AUTOSAR XML (schema 00048)
standard types defined: boolean, sint16, uint16, uint8
package /VehicleProject
  system System
package /NM
  nm config NmConfig: can-nm-cluster-coupling=coupled-cluster=[TC37X_VCU_CAN00_CAN, TC37X_VCU_CAN01_CAN, TC37X_VCU_CAN03_CAN, TC37X_VCU_CAN12_CAN]
    4 x can nm cluster, all with nm-msg-cycle-time=0.5, nm-network-timeout=2, nm-repeat-message-time=1.5, nm-user-data-length=6, nm-wait-bus-sleep-time=2:
      TC37X_VCU_CAN00_CAN: communication-cluster=TC37X_VCU_CAN00, nm-channel-id=0
        can nm node GWM: nm-if-ecu=GWM_CAN, nm-node-id=28, rx-nm-pdu=VCU_Tx_51Ch_NM_oTC37X_VCU_CAN00, tx-nm-pdu=VCU_Rx_500h_NM_oTC37X_VCU_CAN00, nm-msg-cycle-offset=0, nm-msg-reduced-time=0.32, nm-range-config={lower-can-id=1024, upper-can-id=1151}
        can nm node Tester: nm-if-ecu=Tester_CAN, nm-node-id=28, nm-passive-mode-enabled=true, nm-msg-cycle-offset=0, nm-msg-reduced-time=0.32, nm-range-config={lower-can-id=1024, upper-can-id=1151}
        can nm node VCU: controller=CT_TC37X_VCU_CAN00, nm-if-ecu=VCU_CAN, nm-node-id=28, rx-nm-pdu=VCU_Rx_500h_NM_oTC37X_VCU_CAN00, tx-nm-pdu=VCU_Tx_51Ch_NM_oTC37X_VCU_CAN00, nm-msg-cycle-offset=0, nm-msg-reduced-time=0.32, nm-range-config={lower-can-id=1024, upper-can-id=1151}
      TC37X_VCU_CAN01_CAN: communication-cluster=TC37X_VCU_CAN01, nm-channel-id=1
        can nm node GWM: nm-if-ecu=GWM_CAN, nm-node-id=28, rx-nm-pdu=VCU_Tx_51Ch_NM_oTC37X_VCU_CAN01, tx-nm-pdu=VCU_Rx_500h_NM_oTC37X_VCU_CAN01, nm-msg-cycle-offset=0, nm-msg-reduced-time=0.32, nm-range-config={lower-can-id=1024, upper-can-id=1151}
        can nm node Tester: nm-if-ecu=Tester_CAN, nm-node-id=28, nm-passive-mode-enabled=true, nm-msg-cycle-offset=0, nm-msg-reduced-time=0.32, nm-range-config={lower-can-id=1024, upper-can-id=1151}
        can nm node VCU: controller=CT_TC37X_VCU_CAN01, nm-if-ecu=VCU_CAN, nm-node-id=28, rx-nm-pdu=VCU_Rx_500h_NM_oTC37X_VCU_CAN01, tx-nm-pdu=VCU_Tx_51Ch_NM_oTC37X_VCU_CAN01, nm-msg-cycle-offset=0, nm-msg-reduced-time=0.32, nm-range-config={lower-can-id=1024, upper-can-id=1151}
      TC37X_VCU_CAN03_CAN: communication-cluster=TC37X_VCU_CAN03, nm-channel-id=3
        can nm node GWM: nm-if-ecu=GWM_CAN, nm-node-id=28, rx-nm-pdu=VCU_Tx_51Ch_NM_oTC37X_VCU_CAN03, tx-nm-pdu=VCU_Rx_500h_NM_oTC37X_VCU_CAN03, nm-msg-cycle-offset=0, nm-msg-reduced-time=0.32, nm-range-config={lower-can-id=1024, upper-can-id=1151}
        can nm node Tester: nm-if-ecu=Tester_CAN, nm-node-id=28, nm-passive-mode-enabled=true, nm-msg-cycle-offset=0, nm-msg-reduced-time=0.32, nm-range-config={lower-can-id=1024, upper-can-id=1151}
        can nm node VCU: controller=CT_TC37X_VCU_CAN03, nm-if-ecu=VCU_CAN, nm-node-id=28, rx-nm-pdu=VCU_Rx_500h_NM_oTC37X_VCU_CAN03, tx-nm-pdu=VCU_Tx_51Ch_NM_oTC37X_VCU_CAN03, nm-msg-cycle-offset=0, nm-msg-reduced-time=0.32, nm-range-config={lower-can-id=1024, upper-can-id=1151}
      TC37X_VCU_CAN12_CAN: communication-cluster=TC37X_VCU_CAN12, nm-channel-id=2
        can nm node GWM: nm-if-ecu=GWM_CAN, nm-node-id=28, rx-nm-pdu=VCU_Tx_51Ch_NM_oTC37X_VCU_CAN12, tx-nm-pdu=VCU_Rx_500h_NM_oTC37X_VCU_CAN12, nm-msg-cycle-offset=0, nm-msg-reduced-time=0.32, nm-range-config={lower-can-id=1024, upper-can-id=1151}
        can nm node Tester: nm-if-ecu=Tester_CAN, nm-node-id=28, nm-passive-mode-enabled=true, nm-msg-cycle-offset=0, nm-msg-reduced-time=0.32, nm-range-config={lower-can-id=1024, upper-can-id=1151}
        can nm node VCU: controller=CT_TC37X_VCU_CAN12, nm-if-ecu=VCU_CAN, nm-node-id=28, rx-nm-pdu=VCU_Rx_500h_NM_oTC37X_VCU_CAN12, tx-nm-pdu=VCU_Tx_51Ch_NM_oTC37X_VCU_CAN12, nm-msg-cycle-offset=0, nm-msg-reduced-time=0.32, nm-range-config={lower-can-id=1024, upper-can-id=1151}
    nm-if-ecus:
      nm ecu GWM_CAN: nm-node-id-enabled=true, nm-user-data-enabled=true
      nm ecu Tester_CAN: nm-node-id-enabled=true, nm-passive-mode-enabled=true, nm-user-data-enabled=true
      nm ecu VCU_CAN: ecu-instance=VCU, nm-node-id-enabled=true, nm-user-data-enabled=true
package /TP
  can tp config TC37X_VCU_CAN00_CAN: communication-cluster=TC37X_VCU_CAN00, can-tp-ecu{cycle-time-main-function=0.005, ecu-instance=VCU}
    can tp channel TPCH: channel-id=0, channel-mode=FULL-DUPLEX-MODE
    can-tp-connection addressing-format=STANDARD, can-tp-channel=TPCH, data-pdu=Vcu_Uds_Func_Request_Tp_oTC37X_VCU_CAN00, receiver=TN_VCU, ta-type=FUNCTIONAL, tp-sdu=Vcu_Uds_Func_Request_oTC37X_VCU_CAN00, transmitter=TN_Tester:
      ident Vcu_Uds_Func_Request_oTN_Tester
    can-tp-connection addressing-format=STANDARD, can-tp-channel=TPCH, data-pdu=Vcu_Uds_Phy_Request_Tp_oTC37X_VCU_CAN00, flow-control-pdu=Vcu_Uds_Response_Tp_oTC37X_VCU_CAN00, receiver=TN_VCU, ta-type=PHYSICAL, tp-sdu=Vcu_Uds_Phy_Request_oTC37X_VCU_CAN00, transmitter=TN_Tester:
      ident Vcu_Uds_Phy_Request_oTN_VCU
    can-tp-connection addressing-format=STANDARD, can-tp-channel=TPCH, data-pdu=Vcu_Uds_Response_Tp_oTC37X_VCU_CAN00, flow-control-pdu=Vcu_Uds_Phy_Request_Tp_oTC37X_VCU_CAN00, receiver=TN_Tester, ta-type=PHYSICAL, tp-sdu=Vcu_Uds_Response_oTC37X_VCU_CAN00, transmitter=TN_VCU:
      ident Vcu_Uds_Response_oTN_VCU
    can tp node TN_Tester
    can tp node TN_VCU: connector=CN_TC37X_VCU_CAN00
  lin tp config LIN00: communication-cluster=LIN00
    8 x tp address:
      TA_0x005B: tp-address=91
      TA_0x0062: tp-address=98
      TA_0x0063: tp-address=99
      TA_0x0064: tp-address=100
      TA_0x0065: tp-address=101
      TA_0x0074: tp-address=116
      TA_0x0075: tp-address=117
      TA_0x007E: tp-address=126
    tp-connections:
      data-pdu=MasterReq_Tp_oLIN00, lin-tp-n-sdu=MasterReq_oLIN00, multicast=LIN00/TA_0x007E, receiver=[TN_0x005B_HVCH, TN_0x0062_ERV, TN_0x0063_EXV_1, TN_0x0064_EXV_2, TN_0x0065_SVA, TN_0x0074_PMP_1, TN_0x0075_PMP_2], transmitter=LIN00/TN_Master
      data-pdu=SlaveResp_Tp_oLIN00, flow-control=MasterReq_Tp_oLIN00, lin-tp-n-sdu=SlaveResp_HVCH_oLIN00, receiver=LIN00/TN_Master, transmitter=TN_0x005B_HVCH
      data-pdu=SlaveResp_Tp_oLIN00, flow-control=MasterReq_Tp_oLIN00, lin-tp-n-sdu=SlaveResp_ERV_oLIN00, receiver=LIN00/TN_Master, transmitter=TN_0x0062_ERV
      data-pdu=SlaveResp_Tp_oLIN00, flow-control=MasterReq_Tp_oLIN00, lin-tp-n-sdu=SlaveResp_EXV_1_oLIN00, receiver=LIN00/TN_Master, transmitter=TN_0x0063_EXV_1
      data-pdu=SlaveResp_Tp_oLIN00, flow-control=MasterReq_Tp_oLIN00, lin-tp-n-sdu=SlaveResp_EXV_2_oLIN00, receiver=LIN00/TN_Master, transmitter=TN_0x0064_EXV_2
      data-pdu=SlaveResp_Tp_oLIN00, flow-control=MasterReq_Tp_oLIN00, lin-tp-n-sdu=SlaveResp_SVA_oLIN00, receiver=LIN00/TN_Master, transmitter=TN_0x0065_SVA
      data-pdu=SlaveResp_Tp_oLIN00, flow-control=MasterReq_Tp_oLIN00, lin-tp-n-sdu=SlaveResp_PMP_1_oLIN00, receiver=LIN00/TN_Master, transmitter=TN_0x0074_PMP_1
      data-pdu=SlaveResp_Tp_oLIN00, flow-control=MasterReq_Tp_oLIN00, lin-tp-n-sdu=SlaveResp_PMP_2_oLIN00, receiver=LIN00/TN_Master, transmitter=TN_0x0075_PMP_2
      data-pdu=MasterReq_Tp_oLIN00, flow-control=SlaveResp_Tp_oLIN00, lin-tp-n-sdu=MasterReq_HVCH_oLIN00, receiver=TN_0x005B_HVCH, transmitter=LIN00/TN_Master
      data-pdu=MasterReq_Tp_oLIN00, flow-control=SlaveResp_Tp_oLIN00, lin-tp-n-sdu=MasterReq_ERV_oLIN00, receiver=TN_0x0062_ERV, transmitter=LIN00/TN_Master
      data-pdu=MasterReq_Tp_oLIN00, flow-control=SlaveResp_Tp_oLIN00, lin-tp-n-sdu=MasterReq_EXV_1_oLIN00, receiver=TN_0x0063_EXV_1, transmitter=LIN00/TN_Master
      data-pdu=MasterReq_Tp_oLIN00, flow-control=SlaveResp_Tp_oLIN00, lin-tp-n-sdu=MasterReq_EXV_2_oLIN00, receiver=TN_0x0064_EXV_2, transmitter=LIN00/TN_Master
      data-pdu=MasterReq_Tp_oLIN00, flow-control=SlaveResp_Tp_oLIN00, lin-tp-n-sdu=MasterReq_SVA_oLIN00, receiver=TN_0x0065_SVA, transmitter=LIN00/TN_Master
      data-pdu=MasterReq_Tp_oLIN00, flow-control=SlaveResp_Tp_oLIN00, lin-tp-n-sdu=MasterReq_PMP_1_oLIN00, receiver=TN_0x0074_PMP_1, transmitter=LIN00/TN_Master
      data-pdu=MasterReq_Tp_oLIN00, flow-control=SlaveResp_Tp_oLIN00, lin-tp-n-sdu=MasterReq_PMP_2_oLIN00, receiver=TN_0x0075_PMP_2, transmitter=LIN00/TN_Master
    8 x lin tp node:
      TN_0x005B_HVCH: tp-address=TA_0x005B
      TN_0x0062_ERV: tp-address=TA_0x0062
      TN_0x0063_EXV_1: tp-address=TA_0x0063
      TN_0x0064_EXV_2: tp-address=TA_0x0064
      TN_0x0065_SVA: tp-address=TA_0x0065
      TN_0x0074_PMP_1: tp-address=TA_0x0074
      TN_0x0075_PMP_2: tp-address=TA_0x0075
      TN_Master: connector=CN_LIN00
  lin tp config LIN01: communication-cluster=LIN01
    tp address TA_0x0052: tp-address=82
    tp address TA_0x007E: tp-address=126
    tp-connections:
      data-pdu=MasterReq_Tp_oLIN01, lin-tp-n-sdu=MasterReq_oLIN01, multicast=LIN01/TA_0x007E, receiver=TN_0x0052_GWM, transmitter=LIN01/TN_Master
      data-pdu=SlaveResp_Tp_oLIN01, flow-control=MasterReq_Tp_oLIN01, lin-tp-n-sdu=SlaveResp_GWM_oLIN01, receiver=LIN01/TN_Master, transmitter=TN_0x0052_GWM
      data-pdu=MasterReq_Tp_oLIN01, flow-control=SlaveResp_Tp_oLIN01, lin-tp-n-sdu=MasterReq_GWM_oLIN01, receiver=TN_0x0052_GWM, transmitter=LIN01/TN_Master
    lin tp node TN_0x0052_GWM: tp-address=TA_0x0052
    lin tp node TN_Master: connector=CN_LIN01
package /Cluster
  5 x can cluster, all with baudrate=500000, protocol-name=CAN:
    KAMA_FP_EPT_0303
      can physical channel CHNL: comm-connectors=CN_KAMA_FP_EPT_0303
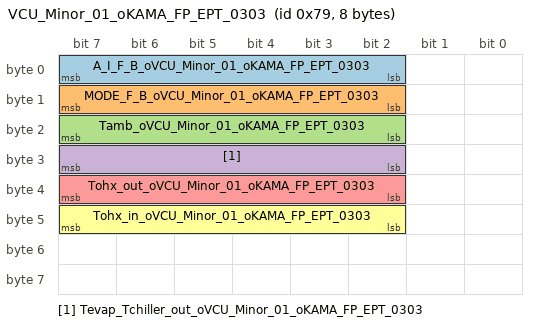
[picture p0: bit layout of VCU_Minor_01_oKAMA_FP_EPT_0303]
        frame VCU_Minor_01_oKAMA_FP_EPT_0303: id 0x79, from VCU, frame-length=8, can-addressing-mode=STANDARD
          pdu VCU_Minor_01_oKAMA_FP_EPT_0303: length=8, minimum-delay=0, transmission-mode-false-timing=cyclic-timing={time-offset=0, time-period=0.02}, transmission-mode-true-timing=cyclic-timing={time-offset=0, time-period=0.02}, unused-bit-pattern=0
            signal A_I_F_B_oVCU_Minor_01_oKAMA_FP_EPT_0303: start 7, 6 bit, big-endian, i-signal-type=PRIMITIVE, init-value=0, base-type=uint8, compu {phys=raw*0.1 for raw 0..50; unit V}, range raw 0..50, unit=V, transfer-property=PENDING
            signal MODE_F_B_oVCU_Minor_01_oKAMA_FP_EPT_0303: start 15, 6 bit, big-endian, i-signal-type=PRIMITIVE, init-value=0, base-type=uint8, compu {phys=raw*0.1 for raw 0..50; unit V}, range raw 0..50, unit=V, transfer-property=PENDING
            signal Tamb_oVCU_Minor_01_oKAMA_FP_EPT_0303: start 23, 6 bit, big-endian, i-signal-type=PRIMITIVE, init-value=0, base-type=uint8, compu {phys=raw*0.1 for raw 0..50; unit V}, range raw 0..50, unit=V, transfer-property=PENDING
            signal Tevap_Tchiller_out_oVCU_Minor_01_oKAMA_FP_EPT_0303: start 31, 6 bit, big-endian, i-signal-type=PRIMITIVE, init-value=0, base-type=uint8, compu {phys=raw*0.1 for raw 0..50; unit V}, range raw 0..50, unit=V, transfer-property=PENDING
            signal Tohx_out_oVCU_Minor_01_oKAMA_FP_EPT_0303: start 39, 6 bit, big-endian, i-signal-type=PRIMITIVE, init-value=0, base-type=uint8, compu {phys=raw*0.1 for raw 0..50; unit V}, range raw 0..50, unit=V, transfer-property=PENDING
            signal Tohx_in_oVCU_Minor_01_oKAMA_FP_EPT_0303: start 47, 6 bit, big-endian, i-signal-type=PRIMITIVE, init-value=0, base-type=uint8, compu {phys=raw*0.1 for raw 0..50; unit V}, range raw 0..50, unit=V, transfer-property=PENDING
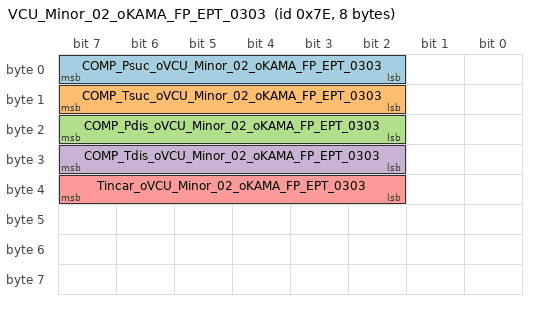
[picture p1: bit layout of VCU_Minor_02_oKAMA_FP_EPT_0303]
        frame VCU_Minor_02_oKAMA_FP_EPT_0303: id 0x7E, from VCU, frame-length=8, can-addressing-mode=STANDARD
          pdu VCU_Minor_02_oKAMA_FP_EPT_0303: length=8, minimum-delay=0, transmission-mode-false-timing=cyclic-timing={time-offset=0, time-period=0.02}, transmission-mode-true-timing=cyclic-timing={time-offset=0, time-period=0.02}, unused-bit-pattern=0
            signal COMP_Psuc_oVCU_Minor_02_oKAMA_FP_EPT_0303: start 7, 6 bit, big-endian, i-signal-type=PRIMITIVE, init-value=0, base-type=uint8, compu {phys=raw*0.1 for raw 0..50; unit V}, range raw 0..50, unit=V, transfer-property=PENDING
            signal COMP_Tsuc_oVCU_Minor_02_oKAMA_FP_EPT_0303: start 15, 6 bit, big-endian, i-signal-type=PRIMITIVE, init-value=0, base-type=uint8, compu {phys=raw*0.1 for raw 0..50; unit V}, range raw 0..50, unit=V, transfer-property=PENDING
            signal COMP_Pdis_oVCU_Minor_02_oKAMA_FP_EPT_0303: start 23, 6 bit, big-endian, i-signal-type=PRIMITIVE, init-value=0, base-type=uint8, compu {phys=raw*0.1 for raw 0..50; unit V}, range raw 0..50, unit=V, transfer-property=PENDING
            signal COMP_Tdis_oVCU_Minor_02_oKAMA_FP_EPT_0303: start 31, 6 bit, big-endian, i-signal-type=PRIMITIVE, init-value=0, base-type=uint8, compu {phys=raw*0.1 for raw 0..50; unit V}, range raw 0..50, unit=V, transfer-property=PENDING
            signal Tincar_oVCU_Minor_02_oKAMA_FP_EPT_0303: start 39, 6 bit, big-endian, i-signal-type=PRIMITIVE, init-value=0, base-type=uint8, compu {phys=raw*0.1 for raw 0..50; unit V}, range raw 0..50, unit=V, transfer-property=PENDING
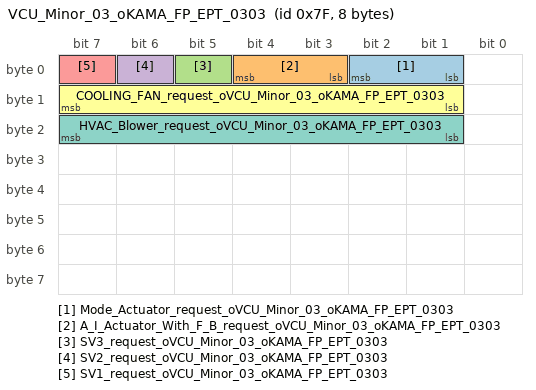
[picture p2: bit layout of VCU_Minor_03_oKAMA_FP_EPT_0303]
        frame VCU_Minor_03_oKAMA_FP_EPT_0303: id 0x7F, to VCU, frame-length=8, can-addressing-mode=STANDARD
          pdu VCU_Minor_03_oKAMA_FP_EPT_0303: length=8, minimum-delay=0, transmission-mode-false-timing=cyclic-timing={time-offset=0, time-period=0.02}, transmission-mode-true-timing=cyclic-timing={time-offset=0, time-period=0.02}, unused-bit-pattern=0
            signal Mode_Actuator_request_oVCU_Minor_03_oKAMA_FP_EPT_0303: start 2, 2 bit, big-endian, i-signal-type=PRIMITIVE, init-value=0, base-type=uint8, compu {0=Cx0_Stop, 1=Cx1_Request_corotation, 2=Cx2_Request_revrsal}, range raw 0..2, transfer-property=PENDING, to VCU
            signal A_I_Actuator_With_F_B_request_oVCU_Minor_03_oKAMA_FP_EPT_0303: start 4, 2 bit, big-endian, i-signal-type=PRIMITIVE, init-value=0, base-type=uint8, compu {0=Cx0_Stop, 1=Cx1_Request_corotation, 2=Cx2_Request_revrsal}, range raw 0..2, transfer-property=PENDING, to VCU
            signal SV3_request_oVCU_Minor_03_oKAMA_FP_EPT_0303: start 5, 1 bit, big-endian, i-signal-type=PRIMITIVE, init-value=0, base-type=boolean, compu {0=Cx0_OFF, 1=Cx1_ON}, range raw 0..1, transfer-property=PENDING, to VCU
            signal SV2_request_oVCU_Minor_03_oKAMA_FP_EPT_0303: start 6, 1 bit, big-endian, i-signal-type=PRIMITIVE, init-value=0, base-type=boolean, compu {0=Cx0_OFF, 1=Cx1_ON}, range raw 0..1, transfer-property=PENDING, to VCU
            signal SV1_request_oVCU_Minor_03_oKAMA_FP_EPT_0303: start 7, 1 bit, big-endian, i-signal-type=PRIMITIVE, init-value=0, base-type=boolean, compu {0=Cx0_OFF, 1=Cx1_ON}, range raw 0..1, transfer-property=PENDING, to VCU
            signal COOLING_FAN_request_oVCU_Minor_03_oKAMA_FP_EPT_0303: start 15, 7 bit, big-endian, i-signal-type=PRIMITIVE, init-value=0, base-type=uint8, compu {identical}, range raw 0..100, unit=%, transfer-property=PENDING, to VCU
            signal HVAC_Blower_request_oVCU_Minor_03_oKAMA_FP_EPT_0303: start 23, 7 bit, big-endian, i-signal-type=PRIMITIVE, init-value=0, base-type=uint8, compu {identical}, range raw 0..100, unit=%, transfer-property=PENDING, to VCU
    TC37X_VCU_CAN00  # VCU_CAN00
      can physical channel CHNL: comm-connectors=CN_TC37X_VCU_CAN00
        frame VCU_Rx_500h_NM_oTC37X_VCU_CAN00: id 0x500, to VCU, frame-length=8, can-addressing-mode=STANDARD
          nm pdu VCU_Rx_500h_NM_oTC37X_VCU_CAN00: length=8, unused-bit-pattern=0
        frame VCU_Tx_51Ch_NM_oTC37X_VCU_CAN00: id 0x51C, from VCU, frame-length=8, can-addressing-mode=STANDARD
          nm pdu VCU_Tx_51Ch_NM_oTC37X_VCU_CAN00: length=8, unused-bit-pattern=0
        frame Vcu_Uds_Func_Request_oTC37X_VCU_CAN00: id 0x700, to VCU, frame-length=8, can-addressing-mode=STANDARD
          n pdu Vcu_Uds_Func_Request_Tp_oTC37X_VCU_CAN00: length=8
        frame Vcu_Uds_Phy_Request_oTC37X_VCU_CAN00: id 0x701, to VCU, frame-length=8, can-addressing-mode=STANDARD
          n pdu Vcu_Uds_Phy_Request_Tp_oTC37X_VCU_CAN00: length=8
        frame Vcu_Uds_Response_oTC37X_VCU_CAN00: id 0x781, from VCU, frame-length=8, can-addressing-mode=STANDARD
          n pdu Vcu_Uds_Response_Tp_oTC37X_VCU_CAN00: length=8
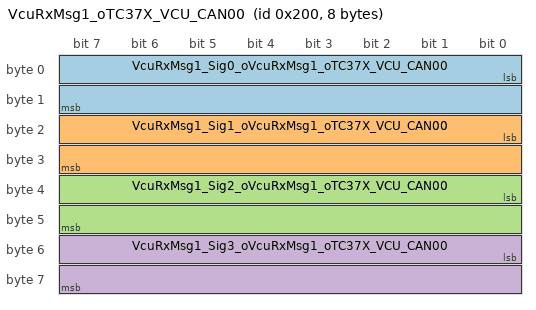
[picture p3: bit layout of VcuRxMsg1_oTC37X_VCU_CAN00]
        frame VcuRxMsg1_oTC37X_VCU_CAN00: id 0x200, to VCU, frame-length=8, can-addressing-mode=STANDARD
          pdu VcuRxMsg1_oTC37X_VCU_CAN00: length=8, minimum-delay=0, transmission-mode-false-timing=cyclic-timing={time-offset=0, time-period=0.5}, transmission-mode-true-timing=cyclic-timing={time-offset=0, time-period=0.5}, unused-bit-pattern=0
            signal VcuRxMsg1_Sig0_oVcuRxMsg1_oTC37X_VCU_CAN00: start 0, 16 bit, little-endian, i-signal-type=PRIMITIVE, init-value=0, base-type=sint16, compu {identical}, range raw -32768..32767, transfer-property=PENDING, to VCU
            signal VcuRxMsg1_Sig1_oVcuRxMsg1_oTC37X_VCU_CAN00: start 16, 16 bit, little-endian, i-signal-type=PRIMITIVE, init-value=0, base-type=sint16, compu {identical}, range raw -32768..32767, transfer-property=PENDING, to VCU
            signal VcuRxMsg1_Sig2_oVcuRxMsg1_oTC37X_VCU_CAN00: start 32, 16 bit, little-endian, i-signal-type=PRIMITIVE, init-value=0, base-type=sint16, compu {identical}, range raw -32768..32767, transfer-property=PENDING, to VCU
            signal VcuRxMsg1_Sig3_oVcuRxMsg1_oTC37X_VCU_CAN00: start 48, 16 bit, little-endian, i-signal-type=PRIMITIVE, init-value=0, base-type=sint16, compu {identical}, range raw -32768..32767, transfer-property=PENDING, to VCU
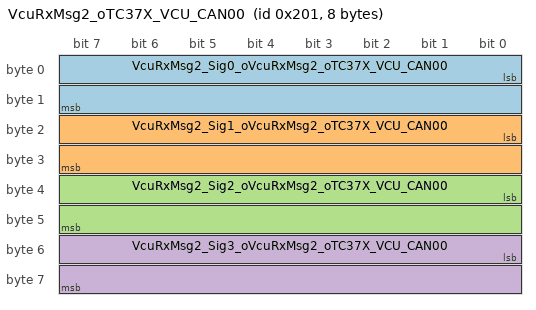
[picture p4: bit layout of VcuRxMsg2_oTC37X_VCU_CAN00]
        frame VcuRxMsg2_oTC37X_VCU_CAN00: id 0x201, to VCU, frame-length=8, can-addressing-mode=STANDARD
          pdu VcuRxMsg2_oTC37X_VCU_CAN00: length=8, minimum-delay=0, transmission-mode-false-timing=cyclic-timing={time-offset=0, time-period=0.5}, transmission-mode-true-timing=cyclic-timing={time-offset=0, time-period=0.5}, unused-bit-pattern=0
            signal VcuRxMsg2_Sig0_oVcuRxMsg2_oTC37X_VCU_CAN00: start 0, 16 bit, little-endian, i-signal-type=PRIMITIVE, init-value=0, base-type=sint16, compu {identical}, range raw -32768..32767, transfer-property=PENDING, to VCU
            signal VcuRxMsg2_Sig1_oVcuRxMsg2_oTC37X_VCU_CAN00: start 16, 16 bit, little-endian, i-signal-type=PRIMITIVE, init-value=0, base-type=sint16, compu {identical}, range raw -32768..32767, transfer-property=PENDING, to VCU
            signal VcuRxMsg2_Sig2_oVcuRxMsg2_oTC37X_VCU_CAN00: start 32, 16 bit, little-endian, i-signal-type=PRIMITIVE, init-value=0, base-type=sint16, compu {identical}, range raw -32768..32767, transfer-property=PENDING, to VCU
            signal VcuRxMsg2_Sig3_oVcuRxMsg2_oTC37X_VCU_CAN00: start 48, 16 bit, little-endian, i-signal-type=PRIMITIVE, init-value=0, base-type=sint16, compu {identical}, range raw -32768..32767, transfer-property=PENDING, to VCU
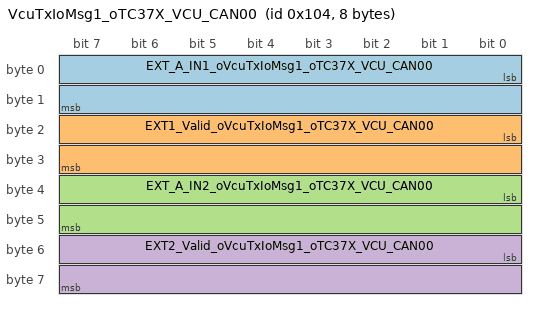
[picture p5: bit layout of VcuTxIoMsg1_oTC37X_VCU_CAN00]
        frame VcuTxIoMsg1_oTC37X_VCU_CAN00: id 0x104, from VCU, frame-length=8, can-addressing-mode=STANDARD
          pdu VcuTxIoMsg1_oTC37X_VCU_CAN00: length=8, minimum-delay=0, transmission-mode-false-timing=cyclic-timing={time-offset=0, time-period=0.5}, transmission-mode-true-timing=cyclic-timing={time-offset=0, time-period=0.5}, unused-bit-pattern=0
            signal EXT_A_IN1_oVcuTxIoMsg1_oTC37X_VCU_CAN00: start 0, 16 bit, little-endian, i-signal-type=PRIMITIVE, init-value=0, base-type=sint16, compu {identical}, range raw -256..255, unit=¡ãC, transfer-property=PENDING
            signal EXT1_Valid_oVcuTxIoMsg1_oTC37X_VCU_CAN00: start 16, 16 bit, little-endian, i-signal-type=PRIMITIVE, init-value=0, base-type=uint16, compu {identical}, range raw 0..1, transfer-property=PENDING
            signal EXT_A_IN2_oVcuTxIoMsg1_oTC37X_VCU_CAN00: start 32, 16 bit, little-endian, i-signal-type=PRIMITIVE, init-value=0, base-type=sint16, compu {identical}, range raw -32768..32767, unit=¡ãC, transfer-property=PENDING
            signal EXT2_Valid_oVcuTxIoMsg1_oTC37X_VCU_CAN00: start 48, 16 bit, little-endian, i-signal-type=PRIMITIVE, init-value=0, base-type=uint16, compu {identical}, range raw 0..1, transfer-property=PENDING
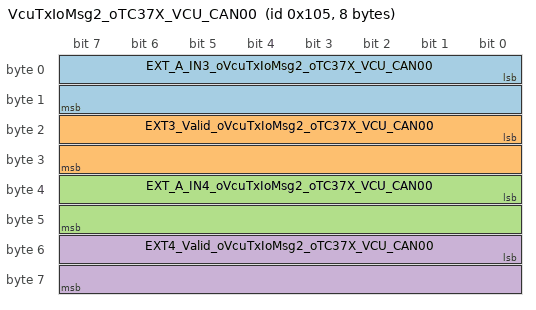
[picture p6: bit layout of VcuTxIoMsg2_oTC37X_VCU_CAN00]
        frame VcuTxIoMsg2_oTC37X_VCU_CAN00: id 0x105, from VCU, frame-length=8, can-addressing-mode=STANDARD
          pdu VcuTxIoMsg2_oTC37X_VCU_CAN00: length=8, minimum-delay=0, transmission-mode-false-timing=cyclic-timing={time-offset=0, time-period=0.5}, transmission-mode-true-timing=cyclic-timing={time-offset=0, time-period=0.5}, unused-bit-pattern=0
            signal EXT_A_IN3_oVcuTxIoMsg2_oTC37X_VCU_CAN00: start 0, 16 bit, little-endian, i-signal-type=PRIMITIVE, init-value=0, base-type=sint16, compu {identical}, range raw -256..255, unit=¡ãC, transfer-property=PENDING
            signal EXT3_Valid_oVcuTxIoMsg2_oTC37X_VCU_CAN00: start 16, 16 bit, little-endian, i-signal-type=PRIMITIVE, init-value=0, base-type=uint16, compu {identical}, range raw 0..1, transfer-property=PENDING
            signal EXT_A_IN4_oVcuTxIoMsg2_oTC37X_VCU_CAN00: start 32, 16 bit, little-endian, i-signal-type=PRIMITIVE, init-value=0, base-type=sint16, compu {identical}, range raw -32768..32767, unit=¡ãC, transfer-property=PENDING
            signal EXT4_Valid_oVcuTxIoMsg2_oTC37X_VCU_CAN00: start 48, 16 bit, little-endian, i-signal-type=PRIMITIVE, init-value=0, base-type=uint16, compu {identical}, range raw 0..1, transfer-property=PENDING
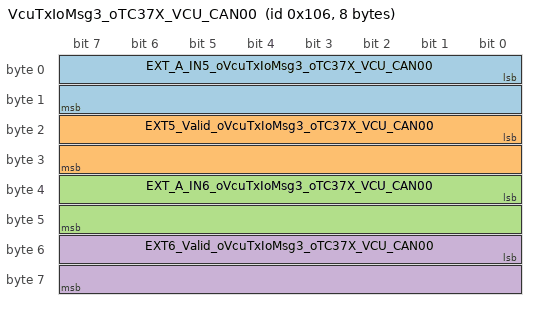
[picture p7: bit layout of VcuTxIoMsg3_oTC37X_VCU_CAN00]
        frame VcuTxIoMsg3_oTC37X_VCU_CAN00: id 0x106, from VCU, frame-length=8, can-addressing-mode=STANDARD
          pdu VcuTxIoMsg3_oTC37X_VCU_CAN00: length=8, minimum-delay=0, transmission-mode-false-timing=cyclic-timing={time-offset=0, time-period=0.5}, transmission-mode-true-timing=cyclic-timing={time-offset=0, time-period=0.5}, unused-bit-pattern=0
            signal EXT_A_IN5_oVcuTxIoMsg3_oTC37X_VCU_CAN00: start 0, 16 bit, little-endian, i-signal-type=PRIMITIVE, init-value=0, base-type=sint16, compu {identical}, range raw -256..255, unit=¡ãC, transfer-property=PENDING
            signal EXT5_Valid_oVcuTxIoMsg3_oTC37X_VCU_CAN00: start 16, 16 bit, little-endian, i-signal-type=PRIMITIVE, init-value=0, base-type=uint16, compu {identical}, range raw 0..1, transfer-property=PENDING
            signal EXT_A_IN6_oVcuTxIoMsg3_oTC37X_VCU_CAN00: start 32, 16 bit, little-endian, i-signal-type=PRIMITIVE, init-value=0, base-type=sint16, compu {identical}, range raw -32768..32767, unit=¡ãC, transfer-property=PENDING
            signal EXT6_Valid_oVcuTxIoMsg3_oTC37X_VCU_CAN00: start 48, 16 bit, little-endian, i-signal-type=PRIMITIVE, init-value=0, base-type=uint16, compu {identical}, range raw 0..1, transfer-property=PENDING
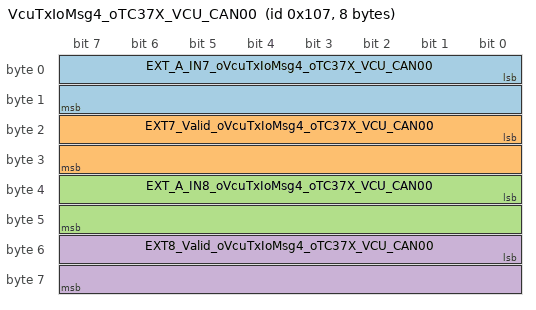
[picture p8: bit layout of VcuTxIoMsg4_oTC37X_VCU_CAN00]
        frame VcuTxIoMsg4_oTC37X_VCU_CAN00: id 0x107, from VCU, frame-length=8, can-addressing-mode=STANDARD
          pdu VcuTxIoMsg4_oTC37X_VCU_CAN00: length=8, minimum-delay=0, transmission-mode-false-timing=cyclic-timing={time-offset=0, time-period=0.5}, transmission-mode-true-timing=cyclic-timing={time-offset=0, time-period=0.5}, unused-bit-pattern=0
            signal EXT_A_IN7_oVcuTxIoMsg4_oTC37X_VCU_CAN00: start 0, 16 bit, little-endian, i-signal-type=PRIMITIVE, init-value=0, base-type=sint16, compu {identical}, range raw -256..255, unit=¡ãC, transfer-property=PENDING
            signal EXT7_Valid_oVcuTxIoMsg4_oTC37X_VCU_CAN00: start 16, 16 bit, little-endian, i-signal-type=PRIMITIVE, init-value=0, base-type=uint16, compu {identical}, range raw 0..1, transfer-property=PENDING
            signal EXT_A_IN8_oVcuTxIoMsg4_oTC37X_VCU_CAN00: start 32, 16 bit, little-endian, i-signal-type=PRIMITIVE, init-value=0, base-type=sint16, compu {identical}, range raw -32768..32767, unit=¡ãC, transfer-property=PENDING
            signal EXT8_Valid_oVcuTxIoMsg4_oTC37X_VCU_CAN00: start 48, 16 bit, little-endian, i-signal-type=PRIMITIVE, init-value=0, base-type=uint16, compu {identical}, range raw 0..1, transfer-property=PENDING
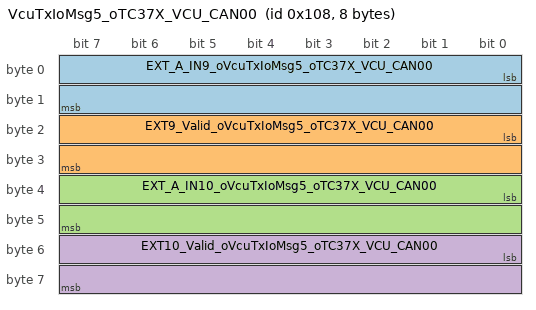
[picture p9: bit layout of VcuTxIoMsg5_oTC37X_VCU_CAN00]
        frame VcuTxIoMsg5_oTC37X_VCU_CAN00: id 0x108, from VCU, frame-length=8, can-addressing-mode=STANDARD
          pdu VcuTxIoMsg5_oTC37X_VCU_CAN00: length=8, minimum-delay=0, transmission-mode-false-timing=cyclic-timing={time-offset=0, time-period=0.5}, transmission-mode-true-timing=cyclic-timing={time-offset=0, time-period=0.5}, unused-bit-pattern=0
            signal EXT_A_IN9_oVcuTxIoMsg5_oTC37X_VCU_CAN00: start 0, 16 bit, little-endian, i-signal-type=PRIMITIVE, init-value=0, base-type=sint16, compu {identical}, range raw -256..255, unit=¡ãC, transfer-property=PENDING
            signal EXT9_Valid_oVcuTxIoMsg5_oTC37X_VCU_CAN00: start 16, 16 bit, little-endian, i-signal-type=PRIMITIVE, init-value=0, base-type=uint16, compu {identical}, range raw 0..1, transfer-property=PENDING
            signal EXT_A_IN10_oVcuTxIoMsg5_oTC37X_VCU_CAN00: start 32, 16 bit, little-endian, i-signal-type=PRIMITIVE, init-value=0, base-type=sint16, compu {identical}, range raw -32768..32767, unit=¡ãC, transfer-property=PENDING
            signal EXT10_Valid_oVcuTxIoMsg5_oTC37X_VCU_CAN00: start 48, 16 bit, little-endian, i-signal-type=PRIMITIVE, init-value=0, base-type=uint16, compu {identical}, range raw 0..1, transfer-property=PENDING
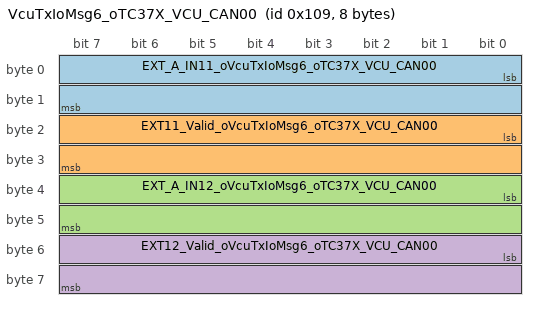
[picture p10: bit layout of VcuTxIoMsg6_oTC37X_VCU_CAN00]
        frame VcuTxIoMsg6_oTC37X_VCU_CAN00: id 0x109, from VCU, frame-length=8, can-addressing-mode=STANDARD
          pdu VcuTxIoMsg6_oTC37X_VCU_CAN00: length=8, minimum-delay=0, transmission-mode-false-timing=cyclic-timing={time-offset=0, time-period=0.5}, transmission-mode-true-timing=cyclic-timing={time-offset=0, time-period=0.5}, unused-bit-pattern=0
            signal EXT_A_IN11_oVcuTxIoMsg6_oTC37X_VCU_CAN00: start 0, 16 bit, little-endian, i-signal-type=PRIMITIVE, init-value=0, base-type=sint16, compu {identical}, range raw -256..255, unit=¡ãC, transfer-property=PENDING
            signal EXT11_Valid_oVcuTxIoMsg6_oTC37X_VCU_CAN00: start 16, 16 bit, little-endian, i-signal-type=PRIMITIVE, init-value=0, base-type=uint16, compu {identical}, range raw 0..1, transfer-property=PENDING
            signal EXT_A_IN12_oVcuTxIoMsg6_oTC37X_VCU_CAN00: start 32, 16 bit, little-endian, i-signal-type=PRIMITIVE, init-value=0, base-type=sint16, compu {identical}, range raw -32768..32767, unit=¡ãC, transfer-property=PENDING
            signal EXT12_Valid_oVcuTxIoMsg6_oTC37X_VCU_CAN00: start 48, 16 bit, little-endian, i-signal-type=PRIMITIVE, init-value=0, base-type=uint16, compu {identical}, range raw 0..1, transfer-property=PENDING
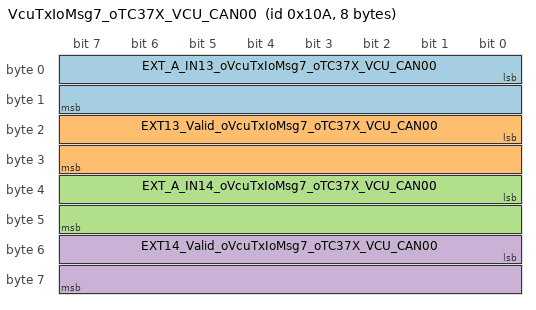
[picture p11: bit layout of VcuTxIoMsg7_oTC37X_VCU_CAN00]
        frame VcuTxIoMsg7_oTC37X_VCU_CAN00: id 0x10A, from VCU, frame-length=8, can-addressing-mode=STANDARD
          pdu VcuTxIoMsg7_oTC37X_VCU_CAN00: length=8, minimum-delay=0, transmission-mode-false-timing=cyclic-timing={time-offset=0, time-period=0.5}, transmission-mode-true-timing=cyclic-timing={time-offset=0, time-period=0.5}, unused-bit-pattern=0
            signal EXT_A_IN13_oVcuTxIoMsg7_oTC37X_VCU_CAN00: start 0, 16 bit, little-endian, i-signal-type=PRIMITIVE, init-value=0, base-type=sint16, compu {identical}, range raw -256..255, unit=¡ãC, transfer-property=PENDING
            signal EXT13_Valid_oVcuTxIoMsg7_oTC37X_VCU_CAN00: start 16, 16 bit, little-endian, i-signal-type=PRIMITIVE, init-value=0, base-type=uint16, compu {identical}, range raw 0..1, transfer-property=PENDING
            signal EXT_A_IN14_oVcuTxIoMsg7_oTC37X_VCU_CAN00: start 32, 16 bit, little-endian, i-signal-type=PRIMITIVE, init-value=0, base-type=sint16, compu {identical}, range raw -32768..32767, unit=¡ãC, transfer-property=PENDING
            signal EXT14_Valid_oVcuTxIoMsg7_oTC37X_VCU_CAN00: start 48, 16 bit, little-endian, i-signal-type=PRIMITIVE, init-value=0, base-type=uint16, compu {identical}, range raw 0..1, transfer-property=PENDING
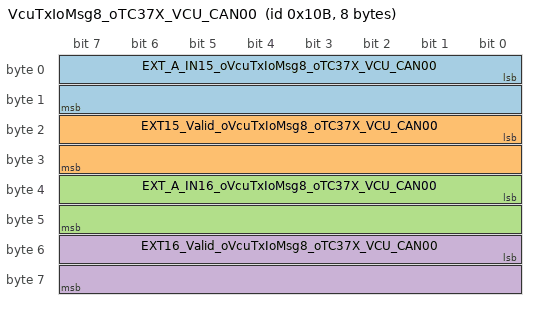
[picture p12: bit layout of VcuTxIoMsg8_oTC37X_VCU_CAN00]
        frame VcuTxIoMsg8_oTC37X_VCU_CAN00: id 0x10B, from VCU, frame-length=8, can-addressing-mode=STANDARD
          pdu VcuTxIoMsg8_oTC37X_VCU_CAN00: length=8, minimum-delay=0, transmission-mode-false-timing=cyclic-timing={time-offset=0, time-period=0.5}, transmission-mode-true-timing=cyclic-timing={time-offset=0, time-period=0.5}, unused-bit-pattern=0
            signal EXT_A_IN15_oVcuTxIoMsg8_oTC37X_VCU_CAN00: start 0, 16 bit, little-endian, i-signal-type=PRIMITIVE, init-value=0, base-type=sint16, compu {identical}, range raw -256..255, unit=¡ãC, transfer-property=PENDING
            signal EXT15_Valid_oVcuTxIoMsg8_oTC37X_VCU_CAN00: start 16, 16 bit, little-endian, i-signal-type=PRIMITIVE, init-value=0, base-type=uint16, compu {identical}, range raw 0..1, transfer-property=PENDING
            signal EXT_A_IN16_oVcuTxIoMsg8_oTC37X_VCU_CAN00: start 32, 16 bit, little-endian, i-signal-type=PRIMITIVE, init-value=0, base-type=sint16, compu {identical}, range raw -32768..32767, unit=¡ãC, transfer-property=PENDING
            signal EXT16_Valid_oVcuTxIoMsg8_oTC37X_VCU_CAN00: start 48, 16 bit, little-endian, i-signal-type=PRIMITIVE, init-value=0, base-type=uint16, compu {identical}, range raw 0..1, transfer-property=PENDING
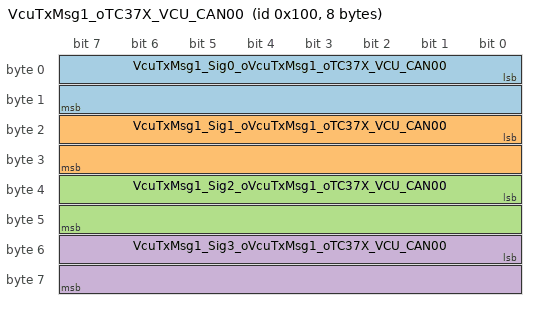
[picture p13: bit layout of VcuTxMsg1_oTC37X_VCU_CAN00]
        frame VcuTxMsg1_oTC37X_VCU_CAN00: id 0x100, from VCU, frame-length=8, can-addressing-mode=STANDARD
          pdu VcuTxMsg1_oTC37X_VCU_CAN00: length=8, minimum-delay=0, transmission-mode-false-timing=cyclic-timing={time-offset=0, time-period=0.5}, transmission-mode-true-timing=cyclic-timing={time-offset=0, time-period=0.5}, unused-bit-pattern=0
            signal VcuTxMsg1_Sig0_oVcuTxMsg1_oTC37X_VCU_CAN00: start 0, 16 bit, little-endian, i-signal-type=PRIMITIVE, init-value=0, base-type=sint16, compu {identical}, range raw -32768..32767, transfer-property=PENDING
            signal VcuTxMsg1_Sig1_oVcuTxMsg1_oTC37X_VCU_CAN00: start 16, 16 bit, little-endian, i-signal-type=PRIMITIVE, init-value=0, base-type=sint16, compu {identical}, range raw -32768..32767, transfer-property=PENDING
            signal VcuTxMsg1_Sig2_oVcuTxMsg1_oTC37X_VCU_CAN00: start 32, 16 bit, little-endian, i-signal-type=PRIMITIVE, init-value=0, base-type=sint16, compu {identical}, range raw -32768..32767, transfer-property=PENDING
            signal VcuTxMsg1_Sig3_oVcuTxMsg1_oTC37X_VCU_CAN00: start 48, 16 bit, little-endian, i-signal-type=PRIMITIVE, init-value=0, base-type=sint16, compu {identical}, range raw -32768..32767, transfer-property=PENDING
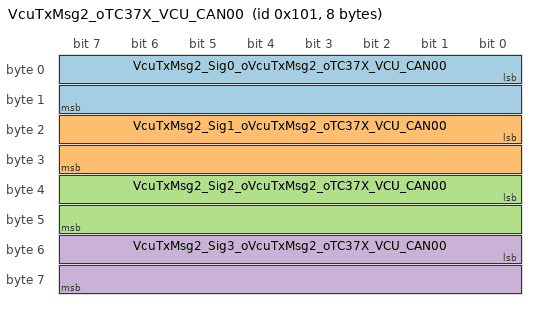
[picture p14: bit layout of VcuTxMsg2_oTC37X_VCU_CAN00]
        frame VcuTxMsg2_oTC37X_VCU_CAN00: id 0x101, from VCU, frame-length=8, can-addressing-mode=STANDARD
          pdu VcuTxMsg2_oTC37X_VCU_CAN00: length=8, minimum-delay=0, transmission-mode-false-timing=cyclic-timing={time-offset=0, time-period=0.5}, transmission-mode-true-timing=cyclic-timing={time-offset=0, time-period=0.5}, unused-bit-pattern=0
            signal VcuTxMsg2_Sig0_oVcuTxMsg2_oTC37X_VCU_CAN00: start 0, 16 bit, little-endian, i-signal-type=PRIMITIVE, init-value=0, base-type=sint16, compu {identical}, range raw -32768..32767, transfer-property=PENDING
            signal VcuTxMsg2_Sig1_oVcuTxMsg2_oTC37X_VCU_CAN00: start 16, 16 bit, little-endian, i-signal-type=PRIMITIVE, init-value=0, base-type=sint16, compu {identical}, range raw -32768..32767, transfer-property=PENDING
            signal VcuTxMsg2_Sig2_oVcuTxMsg2_oTC37X_VCU_CAN00: start 32, 16 bit, little-endian, i-signal-type=PRIMITIVE, init-value=0, base-type=sint16, compu {identical}, range raw -32768..32767, transfer-property=PENDING
            signal VcuTxMsg2_Sig3_oVcuTxMsg2_oTC37X_VCU_CAN00: start 48, 16 bit, little-endian, i-signal-type=PRIMITIVE, init-value=0, base-type=sint16, compu {identical}, range raw -32768..32767, transfer-property=PENDING
        frame XCP_Request_oTC37X_VCU_CAN00: id 0x606, to VCU, frame-length=8, can-addressing-mode=STANDARD
          xcp pdu XCP_Request_oTC37X_VCU_CAN00: length=8
        frame XCP_Response_oTC37X_VCU_CAN00: id 0x607, from VCU, frame-length=8, can-addressing-mode=STANDARD
          xcp pdu XCP_Response_oTC37X_VCU_CAN00: length=8
        pdu triggering PT_Vcu_Uds_Func_Request: pdu=Vcu_Uds_Func_Request_oTC37X_VCU_CAN00, to VCU
        pdu triggering PT_Vcu_Uds_Phy_Request: pdu=Vcu_Uds_Phy_Request_oTC37X_VCU_CAN00, to VCU
        pdu triggering PT_Vcu_Uds_Response: pdu=Vcu_Uds_Response_oTC37X_VCU_CAN00, from VCU
    TC37X_VCU_CAN01  # VCU_CAN01
      can physical channel CHNL: comm-connectors=CN_TC37X_VCU_CAN01
        frame VCU_Rx_500h_NM_oTC37X_VCU_CAN01: id 0x500, to VCU, frame-length=8, can-addressing-mode=STANDARD
          nm pdu VCU_Rx_500h_NM_oTC37X_VCU_CAN01: length=8, unused-bit-pattern=0
        frame VCU_Tx_51Ch_NM_oTC37X_VCU_CAN01: id 0x51C, from VCU, frame-length=8, can-addressing-mode=STANDARD
          nm pdu VCU_Tx_51Ch_NM_oTC37X_VCU_CAN01: length=8, unused-bit-pattern=0
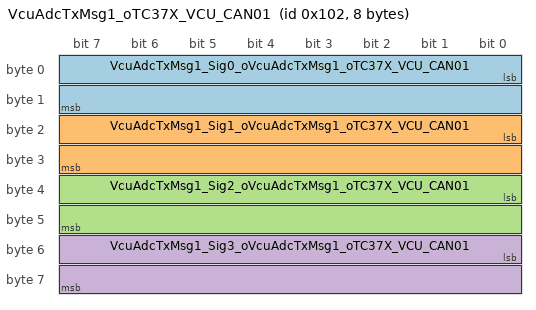
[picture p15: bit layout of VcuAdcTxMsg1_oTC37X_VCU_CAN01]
        frame VcuAdcTxMsg1_oTC37X_VCU_CAN01: id 0x102, from VCU, frame-length=8, can-addressing-mode=STANDARD
          pdu VcuAdcTxMsg1_oTC37X_VCU_CAN01: length=8, minimum-delay=0, transmission-mode-false-timing=cyclic-timing={time-offset=0, time-period=0.5}, transmission-mode-true-timing=cyclic-timing={time-offset=0, time-period=0.5}, unused-bit-pattern=0
            signal VcuAdcTxMsg1_Sig0_oVcuAdcTxMsg1_oTC37X_VCU_CAN01: start 0, 16 bit, little-endian, i-signal-type=PRIMITIVE, init-value=0, base-type=sint16, compu {identical}, range raw -32768..32767, transfer-property=PENDING
            signal VcuAdcTxMsg1_Sig1_oVcuAdcTxMsg1_oTC37X_VCU_CAN01: start 16, 16 bit, little-endian, i-signal-type=PRIMITIVE, init-value=0, base-type=sint16, compu {identical}, range raw -32768..32767, transfer-property=PENDING
            signal VcuAdcTxMsg1_Sig2_oVcuAdcTxMsg1_oTC37X_VCU_CAN01: start 32, 16 bit, little-endian, i-signal-type=PRIMITIVE, init-value=0, base-type=sint16, compu {identical}, range raw -32768..32767, transfer-property=PENDING
            signal VcuAdcTxMsg1_Sig3_oVcuAdcTxMsg1_oTC37X_VCU_CAN01: start 48, 16 bit, little-endian, i-signal-type=PRIMITIVE, init-value=0, base-type=sint16, compu {identical}, range raw -32768..32767, transfer-property=PENDING
        frame VcuAdcTxMsg2_oTC37X_VCU_CAN01: id 0x103, from VCU, frame-length=8, can-addressing-mode=STANDARD
          pdu VcuAdcTxMsg2_oTC37X_VCU_CAN01: length=8, minimum-delay=0, transmission-mode-false-timing=cyclic-timing={time-offset=0, time-period=0.5}, transmission-mode-true-timing=cyclic-timing={time-offset=0, time-period=0.5}, unused-bit-pattern=0
            signal VcuAdcTxMsg2_Sig0_oVcuAdcTxMsg2_oTC37X_VCU_CAN01: start 0, 16 bit, little-endian, i-signal-type=PRIMITIVE, init-value=0, base-type=sint16, compu {identical}, range raw -32768..32767, transfer-property=PENDING
            signal VcuAdcTxMsg2_Sig1_oVcuAdcTxMsg2_oTC37X_VCU_CAN01: start 16, 16 bit, little-endian, i-signal-type=PRIMITIVE, init-value=0, base-type=sint16, compu {identical}, range raw -32768..32767, transfer-property=PENDING
            signal VcuAdcTxMsg2_Sig2_oVcuAdcTxMsg2_oTC37X_VCU_CAN01: start 32, 16 bit, little-endian, i-signal-type=PRIMITIVE, init-value=0, base-type=sint16, compu {identical}, range raw -32768..32767, transfer-property=PENDING
            signal VcuAdcTxMsg2_Sig3_oVcuAdcTxMsg2_oTC37X_VCU_CAN01: start 48, 16 bit, little-endian, i-signal-type=PRIMITIVE, init-value=0, base-type=sint16, compu {identical}, range raw -32768..32767, transfer-property=PENDING
        frame VcuRxMsg3_oTC37X_VCU_CAN01: id 0x202, to VCU, frame-length=8, can-addressing-mode=STANDARD
          pdu VcuRxMsg3_oTC37X_VCU_CAN01: length=8, minimum-delay=0, transmission-mode-false-timing=cyclic-timing={time-offset=0, time-period=0.5}, transmission-mode-true-timing=cyclic-timing={time-offset=0, time-period=0.5}, unused-bit-pattern=0
            signal VcuRxMsg3_Sig0_oVcuRxMsg3_oTC37X_VCU_CAN01: start 0, 16 bit, little-endian, i-signal-type=PRIMITIVE, init-value=0, base-type=sint16, compu {identical}, range raw -32768..32767, transfer-property=PENDING, to VCU
            signal VcuRxMsg3_Sig1_oVcuRxMsg3_oTC37X_VCU_CAN01: start 16, 16 bit, little-endian, i-signal-type=PRIMITIVE, init-value=0, base-type=sint16, compu {identical}, range raw -32768..32767, transfer-property=PENDING, to VCU
            signal VcuRxMsg3_Sig2_oVcuRxMsg3_oTC37X_VCU_CAN01: start 32, 16 bit, little-endian, i-signal-type=PRIMITIVE, init-value=0, base-type=sint16, compu {identical}, range raw -32768..32767, transfer-property=PENDING, to VCU
            signal VcuRxMsg3_Sig3_oVcuRxMsg3_oTC37X_VCU_CAN01: start 48, 16 bit, little-endian, i-signal-type=PRIMITIVE, init-value=0, base-type=sint16, compu {identical}, range raw -32768..32767, transfer-property=PENDING, to VCU
        frame VcuRxMsg4_oTC37X_VCU_CAN01: id 0x203, to VCU, frame-length=8, can-addressing-mode=STANDARD
          pdu VcuRxMsg4_oTC37X_VCU_CAN01: length=8, minimum-delay=0, transmission-mode-false-timing=cyclic-timing={time-offset=0, time-period=0.5}, transmission-mode-true-timing=cyclic-timing={time-offset=0, time-period=0.5}, unused-bit-pattern=0
            signal VcuRxMsg4_Sig0_oVcuRxMsg4_oTC37X_VCU_CAN01: start 0, 16 bit, little-endian, i-signal-type=PRIMITIVE, init-value=0, base-type=sint16, compu {identical}, range raw -32768..32767, transfer-property=PENDING, to VCU
            signal VcuRxMsg4_Sig1_oVcuRxMsg4_oTC37X_VCU_CAN01: start 16, 16 bit, little-endian, i-signal-type=PRIMITIVE, init-value=0, base-type=sint16, compu {identical}, range raw -32768..32767, transfer-property=PENDING, to VCU
            signal VcuRxMsg4_Sig2_oVcuRxMsg4_oTC37X_VCU_CAN01: start 32, 16 bit, little-endian, i-signal-type=PRIMITIVE, init-value=0, base-type=sint16, compu {identical}, range raw -32768..32767, transfer-property=PENDING, to VCU
            signal VcuRxMsg4_Sig3_oVcuRxMsg4_oTC37X_VCU_CAN01: start 48, 16 bit, little-endian, i-signal-type=PRIMITIVE, init-value=0, base-type=sint16, compu {identical}, range raw -32768..32767, transfer-property=PENDING, to VCU
    TC37X_VCU_CAN03  # VCU_CAN03
      can physical channel CHNL: comm-connectors=CN_TC37X_VCU_CAN03
        frame VCU_Rx_500h_NM_oTC37X_VCU_CAN03: id 0x500, to VCU, frame-length=8, can-addressing-mode=STANDARD
          nm pdu VCU_Rx_500h_NM_oTC37X_VCU_CAN03: length=8, unused-bit-pattern=0
        frame VCU_Tx_51Ch_NM_oTC37X_VCU_CAN03: id 0x51C, from VCU, frame-length=8, can-addressing-mode=STANDARD
          nm pdu VCU_Tx_51Ch_NM_oTC37X_VCU_CAN03: length=8, unused-bit-pattern=0
        frame VcuCan03RxMsg1_oTC37X_VCU_CAN03: id 0x212, to VCU, frame-length=8, can-addressing-mode=STANDARD
          pdu VcuCan03RxMsg1_oTC37X_VCU_CAN03: length=8, minimum-delay=0, transmission-mode-false-timing=cyclic-timing={time-offset=0, time-period=0.5}, transmission-mode-true-timing=cyclic-timing={time-offset=0, time-period=0.5}, unused-bit-pattern=0
            signal VcuRxMsg3_Sig0_oVcuCan03RxMsg1_oTC37X_VCU_CAN03: start 0, 16 bit, little-endian, i-signal-type=PRIMITIVE, init-value=0, base-type=sint16, compu {identical}, range raw -32768..32767, transfer-property=PENDING, to VCU
            signal VcuRxMsg3_Sig1_oVcuCan03RxMsg1_oTC37X_VCU_CAN03: start 16, 16 bit, little-endian, i-signal-type=PRIMITIVE, init-value=0, base-type=sint16, compu {identical}, range raw -32768..32767, transfer-property=PENDING, to VCU
            signal VcuRxMsg3_Sig2_oVcuCan03RxMsg1_oTC37X_VCU_CAN03: start 32, 16 bit, little-endian, i-signal-type=PRIMITIVE, init-value=0, base-type=sint16, compu {identical}, range raw -32768..32767, transfer-property=PENDING, to VCU
            signal VcuRxMsg3_Sig3_oVcuCan03RxMsg1_oTC37X_VCU_CAN03: start 48, 16 bit, little-endian, i-signal-type=PRIMITIVE, init-value=0, base-type=sint16, compu {identical}, range raw -32768..32767, transfer-property=PENDING, to VCU
        frame VcuCan03RxMsg2_oTC37X_VCU_CAN03: id 0x213, to VCU, frame-length=8, can-addressing-mode=STANDARD
          pdu VcuCan03RxMsg2_oTC37X_VCU_CAN03: length=8, minimum-delay=0, transmission-mode-false-timing=cyclic-timing={time-offset=0, time-period=0.5}, transmission-mode-true-timing=cyclic-timing={time-offset=0, time-period=0.5}, unused-bit-pattern=0
            signal VcuRxMsg4_Sig0_oVcuCan03RxMsg2_oTC37X_VCU_CAN03: start 0, 16 bit, little-endian, i-signal-type=PRIMITIVE, init-value=0, base-type=sint16, compu {identical}, range raw -32768..32767, transfer-property=PENDING, to VCU
            signal VcuRxMsg4_Sig1_oVcuCan03RxMsg2_oTC37X_VCU_CAN03: start 16, 16 bit, little-endian, i-signal-type=PRIMITIVE, init-value=0, base-type=sint16, compu {identical}, range raw -32768..32767, transfer-property=PENDING, to VCU
            signal VcuRxMsg4_Sig2_oVcuCan03RxMsg2_oTC37X_VCU_CAN03: start 32, 16 bit, little-endian, i-signal-type=PRIMITIVE, init-value=0, base-type=sint16, compu {identical}, range raw -32768..32767, transfer-property=PENDING, to VCU
            signal VcuRxMsg4_Sig3_oVcuCan03RxMsg2_oTC37X_VCU_CAN03: start 48, 16 bit, little-endian, i-signal-type=PRIMITIVE, init-value=0, base-type=sint16, compu {identical}, range raw -32768..32767, transfer-property=PENDING, to VCU
        frame VcuCan03TxMsg1_oTC37X_VCU_CAN03: id 0x112, from VCU, frame-length=8, can-addressing-mode=STANDARD
          pdu VcuCan03TxMsg1_oTC37X_VCU_CAN03: length=8, minimum-delay=0, transmission-mode-false-timing=cyclic-timing={time-offset=0, time-period=0.5}, transmission-mode-true-timing=cyclic-timing={time-offset=0, time-period=0.5}, unused-bit-pattern=0
            signal VcuAdcTxMsg1_Sig0_oVcuCan03TxMsg1_oTC37X_VCU_CAN03: start 0, 16 bit, little-endian, i-signal-type=PRIMITIVE, init-value=0, base-type=sint16, compu {identical}, range raw -32768..32767, transfer-property=PENDING
            signal VcuAdcTxMsg1_Sig1_oVcuCan03TxMsg1_oTC37X_VCU_CAN03: start 16, 16 bit, little-endian, i-signal-type=PRIMITIVE, init-value=0, base-type=sint16, compu {identical}, range raw -32768..32767, transfer-property=PENDING
            signal VcuAdcTxMsg1_Sig2_oVcuCan03TxMsg1_oTC37X_VCU_CAN03: start 32, 16 bit, little-endian, i-signal-type=PRIMITIVE, init-value=0, base-type=sint16, compu {identical}, range raw -32768..32767, transfer-property=PENDING
            signal VcuAdcTxMsg1_Sig3_oVcuCan03TxMsg1_oTC37X_VCU_CAN03: start 48, 16 bit, little-endian, i-signal-type=PRIMITIVE, init-value=0, base-type=sint16, compu {identical}, range raw -32768..32767, transfer-property=PENDING
        frame VcuCan03TxMsg2_oTC37X_VCU_CAN03: id 0x113, from VCU, frame-length=8, can-addressing-mode=STANDARD
          pdu VcuCan03TxMsg2_oTC37X_VCU_CAN03: length=8, minimum-delay=0, transmission-mode-false-timing=cyclic-timing={time-offset=0, time-period=0.5}, transmission-mode-true-timing=cyclic-timing={time-offset=0, time-period=0.5}, unused-bit-pattern=0
            signal VcuAdcTxMsg2_Sig0_oVcuCan03TxMsg2_oTC37X_VCU_CAN03: start 0, 16 bit, little-endian, i-signal-type=PRIMITIVE, init-value=0, base-type=sint16, compu {identical}, range raw -32768..32767, transfer-property=PENDING
            signal VcuAdcTxMsg2_Sig1_oVcuCan03TxMsg2_oTC37X_VCU_CAN03: start 16, 16 bit, little-endian, i-signal-type=PRIMITIVE, init-value=0, base-type=sint16, compu {identical}, range raw -32768..32767, transfer-property=PENDING
            signal VcuAdcTxMsg2_Sig2_oVcuCan03TxMsg2_oTC37X_VCU_CAN03: start 32, 16 bit, little-endian, i-signal-type=PRIMITIVE, init-value=0, base-type=sint16, compu {identical}, range raw -32768..32767, transfer-property=PENDING
            signal VcuAdcTxMsg2_Sig3_oVcuCan03TxMsg2_oTC37X_VCU_CAN03: start 48, 16 bit, little-endian, i-signal-type=PRIMITIVE, init-value=0, base-type=sint16, compu {identical}, range raw -32768..32767, transfer-property=PENDING
    TC37X_VCU_CAN12  # VCU_CAN12
      can physical channel CHNL: comm-connectors=CN_TC37X_VCU_CAN12
        frame VCU_Rx_500h_NM_oTC37X_VCU_CAN12: id 0x500, to VCU, frame-length=8, can-addressing-mode=STANDARD
          nm pdu VCU_Rx_500h_NM_oTC37X_VCU_CAN12: length=8, unused-bit-pattern=0
        frame VCU_Tx_51Ch_NM_oTC37X_VCU_CAN12: id 0x51C, from VCU, frame-length=8, can-addressing-mode=STANDARD
          nm pdu VCU_Tx_51Ch_NM_oTC37X_VCU_CAN12: length=8, unused-bit-pattern=0
        frame VcuCan12RxMsg3_oTC37X_VCU_CAN12: id 0x33, to VCU, frame-length=8, can-addressing-mode=STANDARD
          pdu VcuCan12RxMsg3_oTC37X_VCU_CAN12: length=8, minimum-delay=0, transmission-mode-false-timing=cyclic-timing={time-offset=0, time-period=0.5}, transmission-mode-true-timing=cyclic-timing={time-offset=0, time-period=0.5}, unused-bit-pattern=0
            signal VcuCan12RxMsg3_Sig0_oVcuCan12RxMsg3_oTC37X_VCU_CAN12: start 0, 16 bit, little-endian, i-signal-type=PRIMITIVE, init-value=0, base-type=sint16, compu {identical}, range raw -32768..32767, transfer-property=PENDING, to VCU
            signal VcuCan12RxMsg3_Sig1_oVcuCan12RxMsg3_oTC37X_VCU_CAN12: start 16, 16 bit, little-endian, i-signal-type=PRIMITIVE, init-value=0, base-type=sint16, compu {identical}, range raw -32768..32767, transfer-property=PENDING, to VCU
            signal VcuCan12RxMsg3_Sig2_oVcuCan12RxMsg3_oTC37X_VCU_CAN12: start 32, 16 bit, little-endian, i-signal-type=PRIMITIVE, init-value=0, base-type=sint16, compu {identical}, range raw -32768..32767, transfer-property=PENDING, to VCU
            signal VcuCan12RxMsg3_Sig3_oVcuCan12RxMsg3_oTC37X_VCU_CAN12: start 48, 16 bit, little-endian, i-signal-type=PRIMITIVE, init-value=0, base-type=sint16, compu {identical}, range raw -32768..32767, transfer-property=PENDING, to VCU
        frame VcuCan12RxMsg4_oTC37X_VCU_CAN12: id 0x32, to VCU, frame-length=8, can-addressing-mode=STANDARD
          pdu VcuCan12RxMsg4_oTC37X_VCU_CAN12: length=8, minimum-delay=0, transmission-mode-false-timing=cyclic-timing={time-offset=0, time-period=0.5}, transmission-mode-true-timing=cyclic-timing={time-offset=0, time-period=0.5}, unused-bit-pattern=0
            signal VcuCan12RxMsg4_Sig0_oVcuCan12RxMsg4_oTC37X_VCU_CAN12: start 0, 16 bit, little-endian, i-signal-type=PRIMITIVE, init-value=0, base-type=sint16, compu {identical}, range raw -32768..32767, transfer-property=PENDING, to VCU
            signal VcuCan12RxMsg4_Sig1_oVcuCan12RxMsg4_oTC37X_VCU_CAN12: start 16, 16 bit, little-endian, i-signal-type=PRIMITIVE, init-value=0, base-type=sint16, compu {identical}, range raw -32768..32767, transfer-property=PENDING, to VCU
            signal VcuCan12RxMsg4_Sig2_oVcuCan12RxMsg4_oTC37X_VCU_CAN12: start 32, 16 bit, little-endian, i-signal-type=PRIMITIVE, init-value=0, base-type=sint16, compu {identical}, range raw -32768..32767, transfer-property=PENDING, to VCU
            signal VcuCan12RxMsg4_Sig3_oVcuCan12RxMsg4_oTC37X_VCU_CAN12: start 48, 16 bit, little-endian, i-signal-type=PRIMITIVE, init-value=0, base-type=sint16, compu {identical}, range raw -32768..32767, transfer-property=PENDING, to VCU
        frame VcuCan12TxMsg1_oTC37X_VCU_CAN12: id 0x35, from VCU, frame-length=8, can-addressing-mode=STANDARD
          pdu VcuCan12TxMsg1_oTC37X_VCU_CAN12: length=8, minimum-delay=0, transmission-mode-false-timing=cyclic-timing={time-offset=0, time-period=0.5}, transmission-mode-true-timing=cyclic-timing={time-offset=0, time-period=0.5}, unused-bit-pattern=0
            signal VcuCan12TxMsg1_Sig0_oVcuCan12TxMsg1_oTC37X_VCU_CAN12: start 0, 16 bit, little-endian, i-signal-type=PRIMITIVE, init-value=0, base-type=sint16, compu {identical}, range raw -32768..32767, transfer-property=PENDING
            signal VcuCan12TxMsg1_Sig1_oVcuCan12TxMsg1_oTC37X_VCU_CAN12: start 16, 16 bit, little-endian, i-signal-type=PRIMITIVE, init-value=0, base-type=sint16, compu {identical}, range raw -32768..32767, transfer-property=PENDING
            signal VcuCan12TxMsg1_Sig2_oVcuCan12TxMsg1_oTC37X_VCU_CAN12: start 32, 16 bit, little-endian, i-signal-type=PRIMITIVE, init-value=0, base-type=sint16, compu {identical}, range raw -32768..32767, transfer-property=PENDING
            signal VcuCan12TxMsg1_Sig3_oVcuCan12TxMsg1_oTC37X_VCU_CAN12: start 48, 16 bit, little-endian, i-signal-type=PRIMITIVE, init-value=0, base-type=sint16, compu {identical}, range raw -32768..32767, transfer-property=PENDING
        frame VcuCan12TxMsg2_oTC37X_VCU_CAN12: id 0x34, from VCU, frame-length=8, can-addressing-mode=STANDARD
          pdu VcuCan12TxMsg2_oTC37X_VCU_CAN12: length=8, minimum-delay=0, transmission-mode-false-timing=cyclic-timing={time-offset=0, time-period=0.5}, transmission-mode-true-timing=cyclic-timing={time-offset=0, time-period=0.5}, unused-bit-pattern=0
            signal VcuCan12TxMsg2_Sig0_oVcuCan12TxMsg2_oTC37X_VCU_CAN12: start 0, 16 bit, little-endian, i-signal-type=PRIMITIVE, init-value=0, base-type=sint16, compu {identical}, range raw -32768..32767, transfer-property=PENDING
            signal VcuCan12TxMsg2_Sig1_oVcuCan12TxMsg2_oTC37X_VCU_CAN12: start 16, 16 bit, little-endian, i-signal-type=PRIMITIVE, init-value=0, base-type=sint16, compu {identical}, range raw -32768..32767, transfer-property=PENDING
            signal VcuCan12TxMsg2_Sig2_oVcuCan12TxMsg2_oTC37X_VCU_CAN12: start 32, 16 bit, little-endian, i-signal-type=PRIMITIVE, init-value=0, base-type=sint16, compu {identical}, range raw -32768..32767, transfer-property=PENDING
            signal VcuCan12TxMsg2_Sig3_oVcuCan12TxMsg2_oTC37X_VCU_CAN12: start 48, 16 bit, little-endian, i-signal-type=PRIMITIVE, init-value=0, base-type=sint16, compu {identical}, range raw -32768..32767, transfer-property=PENDING
  lin cluster LIN00: baudrate=19200, protocol-name=LIN, protocol-version=LIN21  # /*************************************************************************************/ // // Description: // Created: // Author: // Version: // Vehicle Project: // /*************************************************************************************/
    lin physical channel CHNL: comm-connectors=CN_LIN00
      frame EDCU_EXV2_oLIN00: id 0x22, from VCU, frame-length=8, lin-checksum=ENHANCED
        pdu EDCU_EXV2_oLIN00: length=8, unused-bit-pattern=255
          signal EDCU_EXV2_Cmd_Set_Rq_oEDCU_EXV2_oLIN00: start 0, 16 bit, little-endian, i-signal-type=PRIMITIVE, init-value=0, base-type=uint16, compu {identical}, range raw 0..576
          signal EDCU_EXV2_Cmd_Move_Enbl_oEDCU_EXV2_oLIN00: start 16, 1 bit, little-endian, i-signal-type=PRIMITIVE, init-value=0, base-type=boolean, compu {0=Cx0_DSABL, 1=Cx1_ENBL}, range raw 0..1
          signal EDCU_EXV2_Cmd_Init_Rq_oEDCU_EXV2_oLIN00: start 24, 3 bit, little-endian, i-signal-type=PRIMITIVE, init-value=0, base-type=uint8, compu {0=Cx0_NO_RQ, 1=Cx1_START_INIT_SQC, 2=Cx2_WAIT_SQC_FINISH}, range raw 0..7
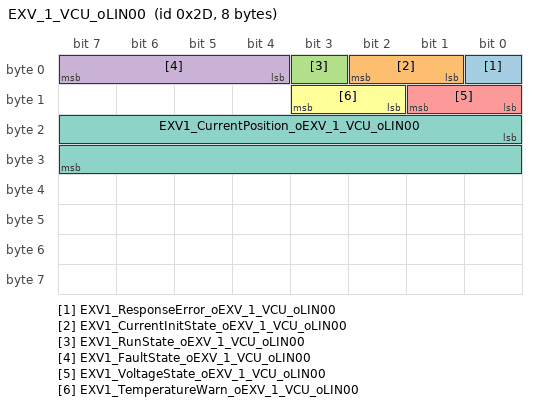
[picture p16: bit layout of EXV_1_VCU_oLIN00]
      frame EXV_1_VCU_oLIN00: id 0x2D, to VCU, frame-length=8, lin-checksum=ENHANCED
        pdu EXV_1_VCU_oLIN00: length=8, unused-bit-pattern=255
          signal EXV1_ResponseError_oEXV_1_VCU_oLIN00: start 0, 1 bit, little-endian, i-signal-type=PRIMITIVE, init-value=0, base-type=boolean, compu {0=Cx0_No_Comm_Error (No Comm Error), 1=Cx1_Comm_Error_Active (Comm Error Active)}, range raw 0..1, to VCU
          signal EXV1_CurrentInitState_oEXV_1_VCU_oLIN00: start 1, 2 bit, little-endian, i-signal-type=PRIMITIVE, init-value=0, base-type=uint8, compu {0=Cx0_NO_INIT, 1=Cx1_INIT_IN_PROCESS, 2=Cx2_Initialized}, range raw 0..3, to VCU
          signal EXV1_RunState_oEXV_1_VCU_oLIN00: start 3, 1 bit, little-endian, i-signal-type=PRIMITIVE, init-value=0, base-type=boolean, compu {0=Cx0_NO_MOVEMENT, 1=Cx1_ACT_MOVING}, range raw 0..1, to VCU
          signal EXV1_FaultState_oEXV_1_VCU_oLIN00: start 4, 4 bit, little-endian, i-signal-type=PRIMITIVE, init-value=0, base-type=uint8, compu {0=Cx0_No_Fault (No Fault), 1=Cx1_COIL_SHRT, 2=Cx2_COIL_OPN, 3=Cx3_Over_temp_shut_down (Over temp shut down), 4=Cx4_Reserved}, range raw 0..4, to VCU
          signal EXV1_VoltageState_oEXV_1_VCU_oLIN00: start 8, 2 bit, little-endian, i-signal-type=PRIMITIVE, init-value=0, base-type=uint8, compu {0=Cx0_Voltage_Range_OK_ (Voltage Range OK), 1=Cx1_Over_Voltage_ (Over Voltage), 2=Cx2_Under_Voltage (Under Voltage)}, range raw 0..2, to VCU
          signal EXV1_TemperatureWarn_oEXV_1_VCU_oLIN00: start 10, 2 bit, little-endian, i-signal-type=PRIMITIVE, init-value=0, base-type=uint8, compu {0=Cx0_OK_, 1=Cx1_WARNING}, range raw 0..1, to VCU
          signal EXV1_CurrentPosition_oEXV_1_VCU_oLIN00: start 16, 16 bit, little-endian, i-signal-type=PRIMITIVE, init-value=0, base-type=uint16, compu {identical}, range raw 0..500, to VCU
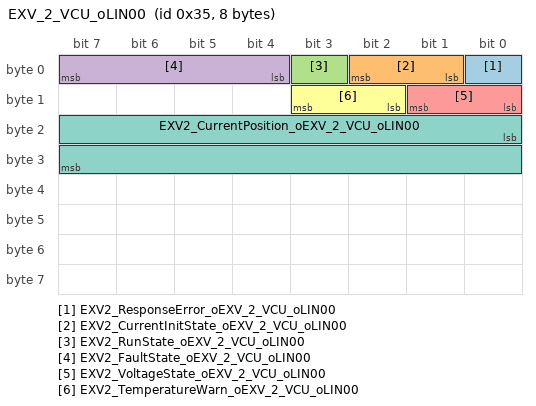
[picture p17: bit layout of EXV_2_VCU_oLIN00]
      frame EXV_2_VCU_oLIN00: id 0x35, to VCU, frame-length=8, lin-checksum=ENHANCED
        pdu EXV_2_VCU_oLIN00: length=8, unused-bit-pattern=255
          signal EXV2_ResponseError_oEXV_2_VCU_oLIN00: start 0, 1 bit, little-endian, i-signal-type=PRIMITIVE, init-value=0, base-type=boolean, compu {0=Cx0_No_Comm_Error (No Comm Error), 1=Cx1_Comm_Error_Active (Comm Error Active)}, range raw 0..1, to VCU
          signal EXV2_CurrentInitState_oEXV_2_VCU_oLIN00: start 1, 2 bit, little-endian, i-signal-type=PRIMITIVE, init-value=0, base-type=uint8, compu {0=Cx0_NO_INIT, 1=Cx1_INIT_IN_PROCESS, 2=Cx2_Initialized}, range raw 0..3, to VCU
          signal EXV2_RunState_oEXV_2_VCU_oLIN00: start 3, 1 bit, little-endian, i-signal-type=PRIMITIVE, init-value=0, base-type=boolean, compu {0=Cx0_NO_MOVEMENT, 1=Cx1_ACT_MOVING}, range raw 0..1, to VCU
          signal EXV2_FaultState_oEXV_2_VCU_oLIN00: start 4, 4 bit, little-endian, i-signal-type=PRIMITIVE, init-value=0, base-type=uint8, compu {0=Cx0_No_Fault (No Fault), 1=Cx1_COIL_SHRT, 2=Cx2_COIL_OPN, 3=Cx3_Over_temp_shut_down (Over temp shut down), 4=Cx4_Reserved}, range raw 0..4, to VCU
          signal EXV2_VoltageState_oEXV_2_VCU_oLIN00: start 8, 2 bit, little-endian, i-signal-type=PRIMITIVE, init-value=0, base-type=uint8, compu {0=Cx0_Voltage_Range_OK_ (Voltage Range OK), 1=Cx1_Over_Voltage_ (Over Voltage), 2=Cx2_Under_Voltage (Under Voltage)}, range raw 0..2, to VCU
          signal EXV2_TemperatureWarn_oEXV_2_VCU_oLIN00: start 10, 2 bit, little-endian, i-signal-type=PRIMITIVE, init-value=0, base-type=uint8, compu {0=Cx0_OK_, 1=Cx1_WARNING}, range raw 0..1, to VCU
          signal EXV2_CurrentPosition_oEXV_2_VCU_oLIN00: start 16, 16 bit, little-endian, i-signal-type=PRIMITIVE, init-value=0, base-type=uint16, compu {identical}, range raw 0..500, to VCU
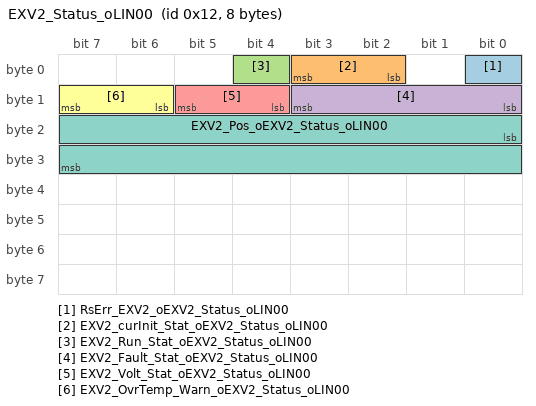
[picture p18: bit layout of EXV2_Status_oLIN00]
      frame EXV2_Status_oLIN00: id 0x12, to VCU, frame-length=8, lin-checksum=ENHANCED
        pdu EXV2_Status_oLIN00: length=8, unused-bit-pattern=255
          signal RsErr_EXV2_oEXV2_Status_oLIN00: start 0, 1 bit, little-endian, i-signal-type=PRIMITIVE, init-value=0, base-type=boolean, compu {0=Cx0_NO_COMM_ERROR (NO COMM ERROR), 1=Cx1_COMM_ERROR_DETECTED (COMM ERROR DETECTED)}, range raw 0..1, to VCU
          signal EXV2_curInit_Stat_oEXV2_Status_oLIN00: start 2, 2 bit, little-endian, i-signal-type=PRIMITIVE, init-value=0, base-type=uint8, compu {0=Cx0_NO_INIT, 1=Cx1_INIT_IN_PROCESS, 2=Cx2_INIT_READY, 3=Cx3_Invalid}, range raw 0..3, to VCU
          signal EXV2_Run_Stat_oEXV2_Status_oLIN00: start 4, 1 bit, little-endian, i-signal-type=PRIMITIVE, init-value=0, base-type=boolean, compu {0=Cx0_NO_MOVEMENT, 1=Cx1_ACT_MOVING}, range raw 0..1, to VCU
          signal EXV2_Fault_Stat_oEXV2_Status_oLIN00: start 8, 4 bit, little-endian, i-signal-type=PRIMITIVE, init-value=0, base-type=uint8, compu {0=Cx0_Actuator_Not_Faulted (Actuator Not Faulted), 1=Cx1_Motor_Coil_shorted (Motor-Coil shorted), 2=Cx2_Motor_Coil_open_load (Motor-Coil open load), 3=Cx3_Over_temperature_shutdown (Over temperature shutdown), 4=Cx4_not_defined (not defined), 5=Cx5_Motor_Stall_ (Motor_Stall?????????)} "Source signal range: [0,4]", range raw 0..5, to VCU
          signal EXV2_Volt_Stat_oEXV2_Status_oLIN00: start 12, 2 bit, little-endian, i-signal-type=PRIMITIVE, init-value=0, base-type=uint8, compu {0=Cx0_VOLT_RANGE_OK, 1=Cx1_OVERVOLTAGE, 2=Cx2_UNDERVOLTAGE, 3=Cx3_not_defined (not defined)} "Source signal range: [0,2]", range raw 0..3, to VCU
          signal EXV2_OvrTemp_Warn_oEXV2_Status_oLIN00: start 14, 2 bit, little-endian, i-signal-type=PRIMITIVE, init-value=0, base-type=uint8, compu {0=Cx0_Ok, 1=Cx1_High_Temperature_Warning (High Temperature Warning), 2=Cx2_not_defined (not defined), 3=Cx3_not_defined (not defined)} "Source signal range: [0,1]", range raw 0..3, to VCU
          signal EXV2_Pos_oEXV2_Status_oLIN00: start 16, 16 bit, little-endian, i-signal-type=PRIMITIVE, init-value=0, base-type=uint16, compu {identical}, range raw 0..576, to VCU
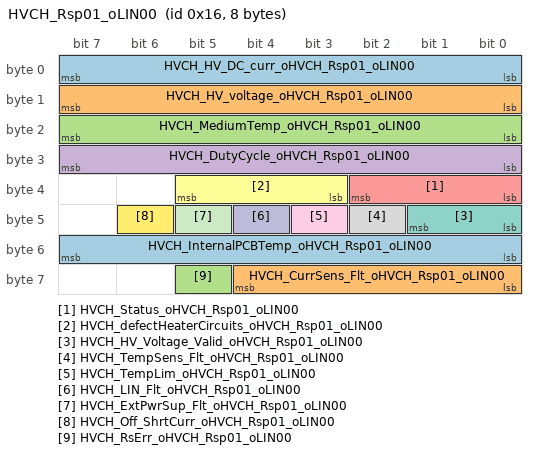
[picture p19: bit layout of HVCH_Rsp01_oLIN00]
      frame HVCH_Rsp01_oLIN00: id 0x16, to VCU, frame-length=8, lin-checksum=ENHANCED
        pdu HVCH_Rsp01_oLIN00: length=8, unused-bit-pattern=255
          signal HVCH_HV_DC_curr_oHVCH_Rsp01_oLIN00: start 0, 8 bit, little-endian, i-signal-type=PRIMITIVE, init-value=0, base-type=uint8, compu {0=Cx00_0x00_0xFE_Valid_value (0x00~0xFE, Valid value), 255=CxFF_invalid, phys=raw*0.25 for raw 1..254; unit A} "Source signal range: [0,254]", range raw 0..255, unit=A, to VCU
          signal HVCH_HV_voltage_oHVCH_Rsp01_oLIN00: start 8, 8 bit, little-endian, i-signal-type=PRIMITIVE, init-value=0, base-type=uint8, compu {0=Cx00_0x00_0xFE_Valid_value (0x00~0xFE, Valid value), 255=CxFF_invalid, phys=raw*2 for raw 1..254; unit V} "Source signal range: [0,254]", range raw 0..255, unit=V, to VCU
          signal HVCH_MediumTemp_oHVCH_Rsp01_oLIN00: start 16, 8 bit, little-endian, i-signal-type=PRIMITIVE, init-value=0, base-type=uint8, compu {0=Cx00_0x00_0xFE_Valid_value (0x00~0xFE, Valid value), 255=CxFF_invalid, phys=raw-50 for raw 1..254; unit celsius} "Source signal range: [0,254]", range raw 0..255, unit=celsius, to VCU
          signal HVCH_DutyCycle_oHVCH_Rsp01_oLIN00: start 24, 8 bit, little-endian, i-signal-type=PRIMITIVE, init-value=50, base-type=uint8, compu {0=Cx00_0x00_0x96_Valid_value (0x00~0x96, Valid value), 255=CxFF_invalid, phys=raw-50 for raw 1..150; unit percent} "Source signal range: [0,150]", range raw 0..255, unit=percent, to VCU
          signal HVCH_Status_oHVCH_Rsp01_oLIN00: start 32, 3 bit, little-endian, i-signal-type=PRIMITIVE, init-value=0, base-type=uint8, compu {0=Cx0_HV_PTC_off_HVCH_OFF (HV PTC off / HVCH_OFF), 1=Cx1_HV_PTC_on_HVCH_ON (HV PTC on / HVCH_ON), 2=Cx2_0x2_0x7_SNA (0x2~0x7, SNA)}, range raw 0..7, to VCU
          signal HVCH_defectHeaterCircuits_oHVCH_Rsp01_oLIN00: start 35, 3 bit, little-endian, i-signal-type=PRIMITIVE, init-value=0, base-type=uint8, compu {0=Cx0_No_defect (No defect), 1=Cx1_Leg_1_defect (Leg 1 defect), 2=Cx2_Leg_2_defect (Leg 2 defect), 3=Cx3_Leg_1_2_defect (Leg 1 + 2 defect), 4=Cx4_Leg_3_defect (Leg 3 defect), 5=Cx5_Leg_1_3_defect (Leg 1 + 3 defect), 6=Cx6_Leg_2_3_defect (Leg 2 + 3 defect), 7=Cx7_Leg_1_2_3_defect (Leg 1 + 2 + 3 defect)}, range raw 0..7, to VCU
          signal HVCH_HV_Voltage_Valid_oHVCH_Rsp01_oLIN00: start 40, 2 bit, little-endian, i-signal-type=PRIMITIVE, init-value=0, base-type=uint8, compu {0=Cx0_NO_HV_detected (NO HV detected), 1=Cx1_HV_valid (HV valid), 2=Cx2_Under_Voltage (Under Voltage), 3=Cx3_Over_Voltage (Over Voltage)}, range raw 0..3, to VCU
          signal HVCH_TempSens_Flt_oHVCH_Rsp01_oLIN00: start 42, 1 bit, little-endian, i-signal-type=PRIMITIVE, init-value=0, base-type=boolean, compu {0=Cx0_No_fault (No fault), 1=Cx1_fault}, range raw 0..1, to VCU
          signal HVCH_TempLim_oHVCH_Rsp01_oLIN00: start 43, 1 bit, little-endian, i-signal-type=PRIMITIVE, init-value=0, base-type=boolean, compu {0=Cx0_No_over_temperature_detected (No over temperature detected), 1=Cx1_Over_temp_situation_active (Over temp. situation active)}, range raw 0..1, to VCU
          signal HVCH_LIN_Flt_oHVCH_Rsp01_oLIN00: start 44, 1 bit, little-endian, i-signal-type=PRIMITIVE, init-value=0, base-type=boolean, compu {0=Cx0_No_LIN_timeout_detected (No LIN timeout detected), 1=Cx1_LIN_timeout_active (LIN timeout active)}, range raw 0..1, to VCU
          signal HVCH_ExtPwrSup_Flt_oHVCH_Rsp01_oLIN00: start 45, 1 bit, little-endian, i-signal-type=PRIMITIVE, init-value=0, base-type=boolean, compu {0=Cx0_Battery_voltage_okay (Battery voltage okay), 1=Cx1_Battery_voltage_off (Battery voltage off)}, range raw 0..1, to VCU
          signal HVCH_Off_ShrtCurr_oHVCH_Rsp01_oLIN00: start 46, 1 bit, little-endian, i-signal-type=PRIMITIVE, init-value=0, base-type=boolean, compu {0=Cx0_No_short_detected (No short detected), 1=Cx1_Short_detected (Short detected)}, range raw 0..1, to VCU
          signal HVCH_InternalPCBTemp_oHVCH_Rsp01_oLIN00: start 48, 8 bit, little-endian, i-signal-type=PRIMITIVE, init-value=0, base-type=uint8, compu {0=Cx00_0x00_0xFE_Valid_value (0x00~0xFE, Valid value), 255=CxFF_invalid, phys=raw-50 for raw 1..254} "Source signal range: [0,254]", range raw 0..255, to VCU
          signal HVCH_CurrSens_Flt_oHVCH_Rsp01_oLIN00: start 56, 5 bit, little-endian, i-signal-type=PRIMITIVE, init-value=0, base-type=uint8, compu {0=Cx00_Diagnostic_pending (Diagnostic pending), 1=Cx01_Diagnostic_passed (Diagnostic passed), 2=Cx02_0x2_0x1F_Reserve (0x2~0x1F, Reserve)}, range raw 0..31, to VCU
          signal HVCH_RsErr_oHVCH_Rsp01_oLIN00: start 61, 1 bit, little-endian, i-signal-type=PRIMITIVE, init-value=0, base-type=boolean, compu {0=Cx0_No_LIN_response_error_detected (No LIN response error detected), 1=Cx1_LIN_response_error_active (LIN response error active)}, range raw 0..1, to VCU
      frame HVCH_Rsp02_oLIN00: id 0x17, to VCU, frame-length=8, lin-checksum=ENHANCED
        pdu HVCH_Rsp02_oLIN00: length=8, unused-bit-pattern=255
          signal HVCH_IntelTemp_oHVCH_Rsp02_oLIN00: start 0, 8 bit, little-endian, i-signal-type=PRIMITIVE, init-value=0, base-type=uint8, compu {0=Cx00_0x00_0xFE_Valid_value (0x00~0xFE, Valid value), 255=CxFF_invalid, phys=raw-50 for raw 1..254; unit celsius} "Source signal range: [0,254]", range raw 0..255, unit=celsius, to VCU
      frame MasterReq_oLIN00: id 0x3C, from VCU, frame-length=8, lin-checksum=CLASSIC
        n pdu MasterReq_Tp_oLIN00: length=8
      frame PMP_Cmd_oLIN00: id 0x24, from VCU, frame-length=8, lin-checksum=ENHANCED
        pdu PMP_Cmd_oLIN00: length=8, unused-bit-pattern=255
          signal ECC_PMP2_SpdSet_oPMP_Cmd_oLIN00: start 8, 8 bit, little-endian, i-signal-type=PRIMITIVE, init-value=0, base-type=uint8, compu {phys=raw*0.4 for raw 0..100; unit %}, range raw 0..100, unit=%
          signal ECC_PMP3_SpdSet_oPMP_Cmd_oLIN00: start 16, 8 bit, little-endian, i-signal-type=PRIMITIVE, init-value=0, base-type=uint8, compu {phys=raw*0.4 for raw 0..100; unit %}, range raw 0..100, unit=%
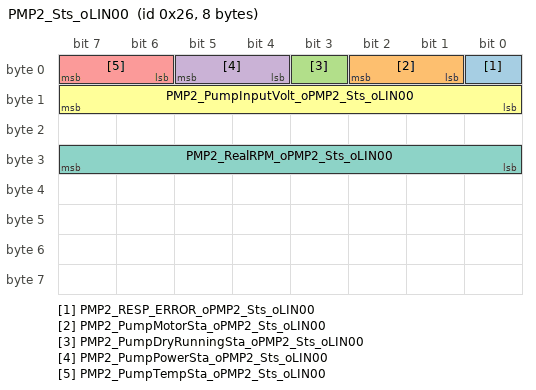
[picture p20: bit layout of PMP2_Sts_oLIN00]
      frame PMP2_Sts_oLIN00: id 0x26, to VCU, frame-length=8, lin-checksum=ENHANCED
        pdu PMP2_Sts_oLIN00: length=8, unused-bit-pattern=255
          signal PMP2_RESP_ERROR_oPMP2_Sts_oLIN00: start 0, 1 bit, little-endian, i-signal-type=PRIMITIVE, init-value=0, base-type=boolean, compu {0=Cx0_Normal, 1=Cx1_Error}, range raw 0..1, to VCU
          signal PMP2_PumpMotorSta_oPMP2_Sts_oLIN00: start 1, 2 bit, little-endian, i-signal-type=PRIMITIVE, init-value=0, base-type=uint8, compu {0=Cx0_Normal, 1=Cx1_ShortCircuit, 2=Cx2_OpenCircuit, 3=Cx3_Stall}, range raw 0..3, to VCU
          signal PMP2_PumpDryRunningSta_oPMP2_Sts_oLIN00: start 3, 1 bit, little-endian, i-signal-type=PRIMITIVE, init-value=0, base-type=boolean, compu {0=Cx0_Normal, 1=Cx1_DryRun}, range raw 0..1, to VCU
          signal PMP2_PumpPowerSta_oPMP2_Sts_oLIN00: start 4, 2 bit, little-endian, i-signal-type=PRIMITIVE, init-value=0, base-type=uint8, compu {0=Cx0_Normal, 1=Cx1_OverVol, 2=Cx2_BelowVol, 3=Cx3_Reserved}, range raw 0..3, to VCU
          signal PMP2_PumpTempSta_oPMP2_Sts_oLIN00: start 6, 2 bit, little-endian, i-signal-type=PRIMITIVE, init-value=0, base-type=uint8, compu {0=Cx0_Normal, 1=Cx1_OverTempReduction, 2=Cx2_OverTempShutDown, 3=Cx3_Reserved}, range raw 0..3, to VCU
          signal PMP2_PumpInputVolt_oPMP2_Sts_oLIN00: start 8, 8 bit, little-endian, i-signal-type=PRIMITIVE, init-value=0, base-type=uint8, compu {phys=raw*0.1 for raw 0..30; unit V}, range raw 0..30, unit=V, to VCU
          signal PMP2_RealRPM_oPMP2_Sts_oLIN00: start 24, 8 bit, little-endian, i-signal-type=PRIMITIVE, init-value=0, base-type=uint8, compu {phys=raw*0.4 for raw 0..100; unit %}, range raw 0..100, unit=%, to VCU
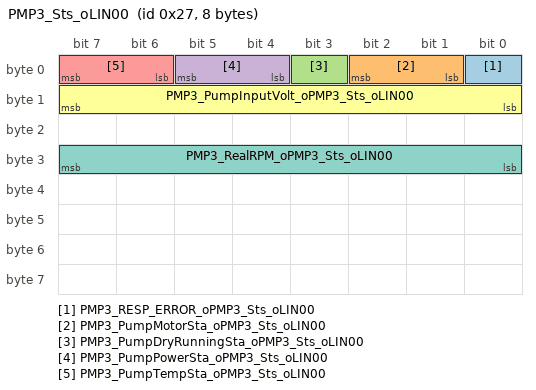
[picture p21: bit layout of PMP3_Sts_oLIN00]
      frame PMP3_Sts_oLIN00: id 0x27, to VCU, frame-length=8, lin-checksum=ENHANCED
        pdu PMP3_Sts_oLIN00: length=8, unused-bit-pattern=255
          signal PMP3_RESP_ERROR_oPMP3_Sts_oLIN00: start 0, 1 bit, little-endian, i-signal-type=PRIMITIVE, init-value=0, base-type=boolean, compu {0=Cx0_Normal, 1=Cx1_Error}, range raw 0..1, to VCU
          signal PMP3_PumpMotorSta_oPMP3_Sts_oLIN00: start 1, 2 bit, little-endian, i-signal-type=PRIMITIVE, init-value=0, base-type=uint8, compu {0=Cx0_Normal, 1=Cx1_ShortCircuit, 2=Cx2_OpenCircuit, 3=Cx3_Stall}, range raw 0..3, to VCU
          signal PMP3_PumpDryRunningSta_oPMP3_Sts_oLIN00: start 3, 1 bit, little-endian, i-signal-type=PRIMITIVE, init-value=0, base-type=boolean, compu {0=Cx0_Normal, 1=Cx1_DryRun}, range raw 0..1, to VCU
          signal PMP3_PumpPowerSta_oPMP3_Sts_oLIN00: start 4, 2 bit, little-endian, i-signal-type=PRIMITIVE, init-value=0, base-type=uint8, compu {0=Cx0_Normal, 1=Cx1_OverVol, 2=Cx2_BelowVol, 3=Cx3_Reserved}, range raw 0..3, to VCU
          signal PMP3_PumpTempSta_oPMP3_Sts_oLIN00: start 6, 2 bit, little-endian, i-signal-type=PRIMITIVE, init-value=0, base-type=uint8, compu {0=Cx0_Normal, 1=Cx1_OverTempReduction, 2=Cx2_OverTempShutDown, 3=Cx3_Reserved}, range raw 0..3, to VCU
          signal PMP3_PumpInputVolt_oPMP3_Sts_oLIN00: start 8, 8 bit, little-endian, i-signal-type=PRIMITIVE, init-value=0, base-type=uint8, compu {phys=raw*0.1 for raw 0..30; unit V}, range raw 0..30, unit=V, to VCU
          signal PMP3_RealRPM_oPMP3_Sts_oLIN00: start 24, 8 bit, little-endian, i-signal-type=PRIMITIVE, init-value=0, base-type=uint8, compu {phys=raw*0.4 for raw 0..100; unit %}, range raw 0..100, unit=%, to VCU
      frame SlaveResp_oLIN00: id 0x3D, to VCU, frame-length=8, lin-checksum=CLASSIC
        n pdu SlaveResp_Tp_oLIN00: length=8
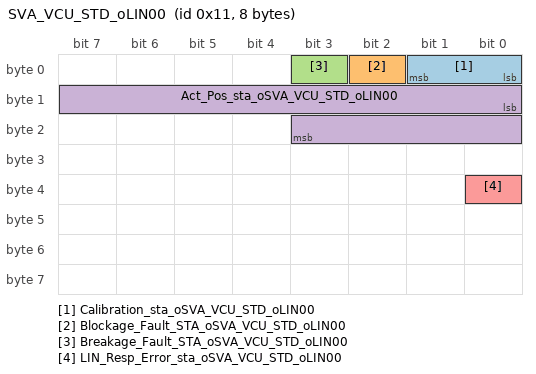
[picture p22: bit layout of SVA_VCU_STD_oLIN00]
      frame SVA_VCU_STD_oLIN00: id 0x11, to VCU, frame-length=8, lin-checksum=ENHANCED
        pdu SVA_VCU_STD_oLIN00: length=8, unused-bit-pattern=255
          signal Calibration_sta_oSVA_VCU_STD_oLIN00: start 0, 2 bit, little-endian, i-signal-type=PRIMITIVE, init-value=0, base-type=uint8, compu {0=Cx0_not_calibration (not calibration), 1=Cx1_calibration_ongoing (calibration ongoing), 2=Cx2_calibration_finished (calibration finished), 3=Cx3_calibration_failed (calibration failed)}, range raw 0..3, to VCU
          signal Blockage_Fault_STA_oSVA_VCU_STD_oLIN00: start 2, 1 bit, little-endian, i-signal-type=PRIMITIVE, init-value=0, base-type=boolean, compu {0=Cx0_False, 1=Cx1_True}, range raw 0..1, to VCU
          signal Breakage_Fault_STA_oSVA_VCU_STD_oLIN00: start 3, 1 bit, little-endian, i-signal-type=PRIMITIVE, init-value=0, base-type=boolean, compu {0=Cx0_False, 1=Cx1_True}, range raw 0..1, to VCU
          signal Act_Pos_sta_oSVA_VCU_STD_oLIN00: start 8, 12 bit, little-endian, i-signal-type=PRIMITIVE, init-value=0, base-type=uint16, compu {phys=raw*0.1-5 for raw 0..3600; unit Degree}, range raw 0..3600, unit=Degree, to VCU
          signal LIN_Resp_Error_sta_oSVA_VCU_STD_oLIN00: start 32, 1 bit, little-endian, i-signal-type=PRIMITIVE, init-value=0, base-type=boolean, compu {0=Cx0_False, 1=Cx1_True}, range raw 0..1, to VCU
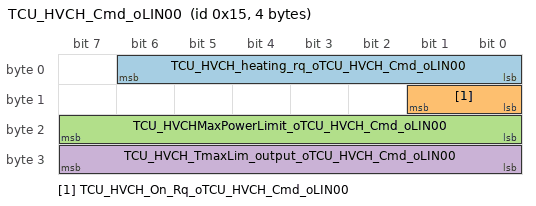
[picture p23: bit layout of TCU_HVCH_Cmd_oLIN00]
      frame TCU_HVCH_Cmd_oLIN00: id 0x15, from VCU, frame-length=4, lin-checksum=ENHANCED
        pdu TCU_HVCH_Cmd_oLIN00: length=4, unused-bit-pattern=255
          signal TCU_HVCH_heating_rq_oTCU_HVCH_Cmd_oLIN00: start 0, 7 bit, little-endian, i-signal-type=PRIMITIVE, init-value=0, base-type=uint8, compu {0=Cx00_Level0, 1=Cx01_Level1, 2=Cx02_Level2, 3=Cx03_Level3, 4=Cx04_Level4, 5=Cx05_Level5, 6=Cx06_Level6, 7=Cx07_Reserve; unit percent}, range raw 0..100, unit=percent
          signal TCU_HVCH_On_Rq_oTCU_HVCH_Cmd_oLIN00: start 8, 2 bit, little-endian, i-signal-type=PRIMITIVE, init-value=0, base-type=uint8, invalid-value=3, compu {0=Cx0_PTC_OFF, 1=Cx1_PTC_ON, 2=Cx2_reserved_RES (reserved / RES), 3=Cx3_SNA}, range raw 0..3
          signal TCU_HVCHMaxPowerLimit_oTCU_HVCH_Cmd_oLIN00: start 16, 8 bit, little-endian, i-signal-type=PRIMITIVE, init-value=0, base-type=uint8, compu {0=Cx00_0x00_0xFE_Valid_value (0x00~0xFE, Valid value), 255=CxFF_invalid, phys=raw*0.04 for raw 1..254; unit KW} "Source signal range: [0,254]", range raw 0..255, unit=KW
          signal TCU_HVCH_TmaxLim_output_oTCU_HVCH_Cmd_oLIN00: start 24, 8 bit, little-endian, i-signal-type=PRIMITIVE, init-value=0, base-type=uint8, compu {0=Cx00_0x00_0xFE_Valid_value (0x00~0xFE, Valid value), 255=CxFF_invalid, phys=raw-50 for raw 1..254; unit celsius} "Source signal range: [0,254]", range raw 0..255, unit=celsius
      frame VCU_EXV_1_oLIN00: id 0x1F, from VCU, frame-length=8, lin-checksum=ENHANCED
        pdu VCU_EXV_1_oLIN00: length=8, unused-bit-pattern=255
          signal TMM_EXV1_PositionRequest_oVCU_EXV_1_oLIN00: start 0, 16 bit, little-endian, i-signal-type=PRIMITIVE, init-value=0, base-type=uint16, compu {identical}, range raw 0..500
          signal TMM_EXV1_EnableRequest_oVCU_EXV_1_oLIN00: start 16, 1 bit, little-endian, i-signal-type=PRIMITIVE, init-value=0, base-type=boolean, compu {0=Cx0_EXVNotEnable, 1=Cx1_EXVEnable}, range raw 0..1
          signal TMM_EXV1_initRequest_oVCU_EXV_1_oLIN00: start 24, 3 bit, little-endian, i-signal-type=PRIMITIVE, init-value=0, base-type=uint8, compu {0=Cx0_NO_RQ, 1=Cx1_InitializationReq_, 2=Cx2_waiting_for_Sequence_to_finish (waiting for Sequence to finish)}, range raw 0..7
      frame VCU_EXV_2_oLIN00: id 0x34, from VCU, frame-length=8, lin-checksum=ENHANCED
        pdu VCU_EXV_2_oLIN00: length=8, unused-bit-pattern=255
          signal TMM_EXV2_PositionRequest_oVCU_EXV_2_oLIN00: start 0, 16 bit, little-endian, i-signal-type=PRIMITIVE, init-value=0, base-type=uint16, compu {identical}, range raw 0..500
          signal TMM_EXV2_EnableRequest_oVCU_EXV_2_oLIN00: start 16, 1 bit, little-endian, i-signal-type=PRIMITIVE, init-value=0, base-type=boolean, compu {0=Cx0_EXVNotEnable, 1=Cx1_EXVEnable}, range raw 0..1
          signal TMM_EXV2_initRequest_oVCU_EXV_2_oLIN00: start 24, 3 bit, little-endian, i-signal-type=PRIMITIVE, init-value=0, base-type=uint8, compu {0=Cx0_NO_RQ, 1=Cx1_InitializationReq_, 2=Cx2_waiting_for_Sequence_to_finish (waiting for Sequence to finish)}, range raw 0..7
      frame VCU_SVA_CMD_oLIN00: id 0x10, from VCU, frame-length=8, lin-checksum=ENHANCED
        pdu VCU_SVA_CMD_oLIN00: length=8, unused-bit-pattern=255
          signal Calibration_cmd_oVCU_SVA_CMD_oLIN00: start 8, 1 bit, little-endian, i-signal-type=PRIMITIVE, init-value=0, base-type=boolean, compu {0=Cx0_Normal, 1=Cx1_SVA_performs_calibration (SVA performs calibration)}, range raw 0..1
          signal Target_Pos_cmd_oVCU_SVA_CMD_oLIN00: start 16, 12 bit, little-endian, i-signal-type=PRIMITIVE, init-value=0, base-type=uint16, compu {phys=raw*0.1-5 for raw 0..3600; unit Degree}, range raw 0..3600, unit=Degree
      pdu triggering PT_MasterReq: pdu=MasterReq_oLIN00, from VCU
      pdu triggering PT_MasterReq_ERV: pdu=MasterReq_ERV_oLIN00, from VCU
      pdu triggering PT_MasterReq_EXV_1: pdu=MasterReq_EXV_1_oLIN00, from VCU
      pdu triggering PT_MasterReq_EXV_2: pdu=MasterReq_EXV_2_oLIN00, from VCU
      pdu triggering PT_MasterReq_HVCH: pdu=MasterReq_HVCH_oLIN00, from VCU
      pdu triggering PT_MasterReq_PMP_1: pdu=MasterReq_PMP_1_oLIN00, from VCU
      pdu triggering PT_MasterReq_PMP_2: pdu=MasterReq_PMP_2_oLIN00, from VCU
      pdu triggering PT_MasterReq_SVA: pdu=MasterReq_SVA_oLIN00, from VCU
      pdu triggering PT_SlaveResp_ERV: pdu=SlaveResp_ERV_oLIN00, to VCU
      pdu triggering PT_SlaveResp_EXV_1: pdu=SlaveResp_EXV_1_oLIN00, to VCU
      pdu triggering PT_SlaveResp_EXV_2: pdu=SlaveResp_EXV_2_oLIN00, to VCU
      pdu triggering PT_SlaveResp_HVCH: pdu=SlaveResp_HVCH_oLIN00, to VCU
      pdu triggering PT_SlaveResp_PMP_1: pdu=SlaveResp_PMP_1_oLIN00, to VCU
      pdu triggering PT_SlaveResp_PMP_2: pdu=SlaveResp_PMP_2_oLIN00, to VCU
      pdu triggering PT_SlaveResp_SVA: pdu=SlaveResp_SVA_oLIN00, to VCU
      lin schedule table TCU_LIN_Schedule: run-mode=RUN-CONTINUOUS
        table-entrys:
          delay=0.01, position-in-table=0, frame-triggering=FT_EDCU_EXV2
          delay=0.01, position-in-table=1, frame-triggering=FT_EXV2_Status
          delay=0.1, position-in-table=2, frame-triggering=FT_VCU_EXV_1
          delay=0.1, position-in-table=3, frame-triggering=FT_EXV_1_VCU
          delay=0.1, position-in-table=4, frame-triggering=FT_VCU_EXV_2
          delay=0.1, position-in-table=5, frame-triggering=FT_EXV_2_VCU
          delay=0.01, position-in-table=6, frame-triggering=FT_PMP_Cmd
          delay=0.01, position-in-table=7, frame-triggering=FT_PMP2_Sts
          delay=0.01, position-in-table=8, frame-triggering=FT_PMP3_Sts
          delay=0.015, position-in-table=9, frame-triggering=FT_VCU_SVA_CMD
          delay=0.015, position-in-table=10, frame-triggering=FT_SVA_VCU_STD
          delay=0.02, position-in-table=11, frame-triggering=FT_TCU_HVCH_Cmd
          delay=0.02, position-in-table=12, frame-triggering=FT_HVCH_Rsp01
          delay=0.02, position-in-table=13, frame-triggering=FT_HVCH_Rsp02
  lin cluster LIN01: baudrate=19200, protocol-name=LIN, protocol-version=LIN21  # LIN4 | /*************************************************************************************/ // // Description: // Created: // Author: // Version: // Vehicle Project: // /*************************************************************************************/
    lin physical channel CHNL: comm-connectors=CN_LIN01
      frame MasterReq_oLIN01: id 0x3C, from VCU, frame-length=8, lin-checksum=CLASSIC
        n pdu MasterReq_Tp_oLIN01: length=8
      frame SlaveResp_oLIN01: id 0x3D, to VCU, frame-length=8, lin-checksum=CLASSIC
        n pdu SlaveResp_Tp_oLIN01: length=8
      frame Vcu_Lin0_RxMsg1_oLIN01: id 0x20, to VCU, frame-length=8, lin-checksum=ENHANCED
        pdu Vcu_Lin0_RxMsg1_oLIN01: length=8, unused-bit-pattern=255
          signal Vcu_Lin0_RxMsg1_Sig1_oVcu_Lin0_RxMsg1_oLIN01: start 0, 8 bit, little-endian, i-signal-type=PRIMITIVE, init-value=0, base-type=uint8, compu {identical}, range raw 0..255, to VCU
          signal Vcu_Lin0_RxMsg1_Sig0_oVcu_Lin0_RxMsg1_oLIN01: start 8, 8 bit, little-endian, i-signal-type=PRIMITIVE, init-value=0, base-type=uint8, compu {identical}, range raw 0..255, to VCU
          signal Vcu_Lin0_RxMsg2_Sig2_oVcu_Lin0_RxMsg1_oLIN01: start 16, 8 bit, little-endian, i-signal-type=PRIMITIVE, init-value=0, base-type=uint8, compu {identical}, range raw 0..255, to VCU
          signal Vcu_Lin0_RxMsg2_Sig3_oVcu_Lin0_RxMsg1_oLIN01: start 24, 8 bit, little-endian, i-signal-type=PRIMITIVE, init-value=0, base-type=uint8, compu {identical}, range raw 0..255, to VCU
      frame Vcu_Lin0_RxMsg2_oLIN01: id 0x21, to VCU, frame-length=8, lin-checksum=ENHANCED
        pdu Vcu_Lin0_RxMsg2_oLIN01: length=8, unused-bit-pattern=255
          signal Vcu_Lin0_RxMsg2_Sig0_oVcu_Lin0_RxMsg2_oLIN01: start 0, 8 bit, little-endian, i-signal-type=PRIMITIVE, init-value=0, base-type=uint8, compu {identical}, range raw 0..255, to VCU
          signal Vcu_Lin0_RxMsg2_Sig1_oVcu_Lin0_RxMsg2_oLIN01: start 8, 8 bit, little-endian, i-signal-type=PRIMITIVE, init-value=0, base-type=uint8, compu {identical}, range raw 0..255, to VCU
          signal Vcu_Lin0_RxMsg2_Sig2_oVcu_Lin0_RxMsg2_oLIN01: start 16, 8 bit, little-endian, i-signal-type=PRIMITIVE, init-value=0, base-type=uint8, compu {identical}, range raw 0..255, to VCU
          signal Vcu_Lin0_RxMsg2_Sig3_oVcu_Lin0_RxMsg2_oLIN01: start 32, 8 bit, little-endian, i-signal-type=PRIMITIVE, init-value=0, base-type=uint8, compu {identical}, range raw 0..255, to VCU
      frame Vcu_Lin0_TxMsg1_oLIN01: id 0x1E, from VCU, frame-length=8, lin-checksum=ENHANCED
        pdu Vcu_Lin0_TxMsg1_oLIN01: length=8, unused-bit-pattern=255
          signal Vcu_Lin0_TxMsg1_Sig0_oVcu_Lin0_TxMsg1_oLIN01: start 0, 8 bit, little-endian, i-signal-type=PRIMITIVE, init-value=0, base-type=uint8, compu {identical}, range raw 0..255
          signal Vcu_Lin0_TxMsg1_Sig1_oVcu_Lin0_TxMsg1_oLIN01: start 8, 8 bit, little-endian, i-signal-type=PRIMITIVE, init-value=0, base-type=uint8, compu {identical}, range raw 0..255
          signal Vcu_Lin0_TxMsg1_Sig2_oVcu_Lin0_TxMsg1_oLIN01: start 16, 8 bit, little-endian, i-signal-type=PRIMITIVE, init-value=0, base-type=uint8, compu {identical}, range raw 0..255
          signal Vcu_Lin0_TxMsg1_Sig3_oVcu_Lin0_TxMsg1_oLIN01: start 24, 8 bit, little-endian, i-signal-type=PRIMITIVE, init-value=0, base-type=uint8, compu {identical}, range raw 0..255
      frame Vcu_Lin0_TxMsg2_oLIN01: id 0x1F, from VCU, frame-length=8, lin-checksum=ENHANCED
        pdu Vcu_Lin0_TxMsg2_oLIN01: length=8, unused-bit-pattern=255
          signal Vcu_Lin0_TxMsg2_Sig0_oVcu_Lin0_TxMsg2_oLIN01: start 0, 8 bit, little-endian, i-signal-type=PRIMITIVE, init-value=0, base-type=uint8, compu {identical}, range raw 0..255
          signal Vcu_Lin0_TxMsg2_Sig1_oVcu_Lin0_TxMsg2_oLIN01: start 8, 8 bit, little-endian, i-signal-type=PRIMITIVE, init-value=0, base-type=uint8, compu {identical}, range raw 0..255
          signal Vcu_Lin0_TxMsg2_Sig2_oVcu_Lin0_TxMsg2_oLIN01: start 16, 8 bit, little-endian, i-signal-type=PRIMITIVE, init-value=0, base-type=uint8, compu {identical}, range raw 0..255
          signal Vcu_Lin0_TxMsg2_Sig3_oVcu_Lin0_TxMsg2_oLIN01: start 24, 8 bit, little-endian, i-signal-type=PRIMITIVE, init-value=0, base-type=uint8, compu {identical}, range raw 0..255
      pdu triggering PT_MasterReq: pdu=MasterReq_oLIN01, from VCU
      pdu triggering PT_MasterReq_GWM: pdu=MasterReq_GWM_oLIN01, from VCU
      pdu triggering PT_SlaveResp_GWM: pdu=SlaveResp_GWM_oLIN01, to VCU
      lin schedule table Vcu_Lin0_Schedule: run-mode=RUN-CONTINUOUS
        table-entrys:
          delay=0.02, position-in-table=0, frame-triggering=FT_Vcu_Lin0_TxMsg1
          delay=0.02, position-in-table=1, frame-triggering=FT_Vcu_Lin0_TxMsg2
          delay=0.02, position-in-table=2, frame-triggering=FT_Vcu_Lin0_RxMsg1
          delay=0.02, position-in-table=3, frame-triggering=FT_Vcu_Lin0_RxMsg2
package /ECU
  ecu instance VCU: associated-com-i-pdu-group=[VCU_oKAMA_FP_EPT_0303_Rx, VCU_oKAMA_FP_EPT_0303_Tx, VCU_oLIN00_Rx, VCU_oLIN00_Tx, VCU_oLIN01_Rx, VCU_oLIN01_Tx, VCU_oTC37X_VCU_CAN00_Rx, VCU_oTC37X_VCU_CAN00_Tx, VCU_oTC37X_VCU_CAN01_Rx, VCU_oTC37X_VCU_CAN01_Tx, VCU_oTC37X_VCU_CAN03_Rx, VCU_oTC37X_VCU_CAN03_Tx, VCU_oTC37X_VCU_CAN12_Rx, VCU_oTC37X_VCU_CAN12_Tx]
    5 x can communication controller:
      CT_KAMA_FP_EPT_0303
      CT_TC37X_VCU_CAN00
      CT_TC37X_VCU_CAN01
      CT_TC37X_VCU_CAN03
      CT_TC37X_VCU_CAN12
    lin master CT_LIN00: protocol-version=LIN21, time-base=0.005, time-base-jitter=0.0001
    lin master CT_LIN01: protocol-version=LIN21, time-base=0.005, time-base-jitter=0.0001
    can communication connector CN_KAMA_FP_EPT_0303: comm-controller=CT_KAMA_FP_EPT_0303
    can communication connector CN_TC37X_VCU_CAN00: comm-controller=CT_TC37X_VCU_CAN00
    can communication connector CN_TC37X_VCU_CAN01: comm-controller=CT_TC37X_VCU_CAN01
    can communication connector CN_TC37X_VCU_CAN03: comm-controller=CT_TC37X_VCU_CAN03
    can communication connector CN_TC37X_VCU_CAN12: comm-controller=CT_TC37X_VCU_CAN12
    lin communication connector CN_LIN00: comm-controller=CT_LIN00
    lin communication connector CN_LIN01: comm-controller=CT_LIN01
package /Gateway
  gateway VCU: ecu=VCU
package /IPDUGroup
  14 x i signal i pdu group:
    VCU_oKAMA_FP_EPT_0303_Rx: communication-direction=IN, i-signal-i-pdus=VCU_Minor_03_oKAMA_FP_EPT_0303
    VCU_oKAMA_FP_EPT_0303_Tx: communication-direction=OUT, i-signal-i-pdus=[VCU_Minor_01_oKAMA_FP_EPT_0303, VCU_Minor_02_oKAMA_FP_EPT_0303]
    VCU_oLIN00_Rx: communication-direction=IN
      i-signal-i-pdus:
        EXV_1_VCU_oLIN00
        EXV_2_VCU_oLIN00
        EXV2_Status_oLIN00
        HVCH_Rsp01_oLIN00
        HVCH_Rsp02_oLIN00
        PMP2_Sts_oLIN00
        PMP3_Sts_oLIN00
        SVA_VCU_STD_oLIN00
    VCU_oLIN00_Tx: communication-direction=OUT, i-signal-i-pdus=[EDCU_EXV2_oLIN00, PMP_Cmd_oLIN00, TCU_HVCH_Cmd_oLIN00, VCU_EXV_1_oLIN00, VCU_EXV_2_oLIN00, VCU_SVA_CMD_oLIN00]
    VCU_oLIN01_Rx: communication-direction=IN, i-signal-i-pdus=[Vcu_Lin0_RxMsg1_oLIN01, Vcu_Lin0_RxMsg2_oLIN01]
    VCU_oLIN01_Tx: communication-direction=OUT, i-signal-i-pdus=[Vcu_Lin0_TxMsg1_oLIN01, Vcu_Lin0_TxMsg2_oLIN01]
    VCU_oTC37X_VCU_CAN00_Rx: communication-direction=IN, i-signal-i-pdus=[VcuRxMsg1_oTC37X_VCU_CAN00, VcuRxMsg2_oTC37X_VCU_CAN00]
    VCU_oTC37X_VCU_CAN00_Tx: communication-direction=OUT
      i-signal-i-pdus:
        VcuTxIoMsg{1..8}_oTC37X_VCU_CAN00
        VcuTxMsg1_oTC37X_VCU_CAN00
        VcuTxMsg2_oTC37X_VCU_CAN00
    VCU_oTC37X_VCU_CAN01_Rx: communication-direction=IN, i-signal-i-pdus=[VcuRxMsg3_oTC37X_VCU_CAN01, VcuRxMsg4_oTC37X_VCU_CAN01]
    VCU_oTC37X_VCU_CAN01_Tx: communication-direction=OUT, i-signal-i-pdus=[VcuAdcTxMsg1_oTC37X_VCU_CAN01, VcuAdcTxMsg2_oTC37X_VCU_CAN01]
    VCU_oTC37X_VCU_CAN03_Rx: communication-direction=IN, i-signal-i-pdus=[VcuCan03RxMsg1_oTC37X_VCU_CAN03, VcuCan03RxMsg2_oTC37X_VCU_CAN03]
    VCU_oTC37X_VCU_CAN03_Tx: communication-direction=OUT, i-signal-i-pdus=[VcuCan03TxMsg1_oTC37X_VCU_CAN03, VcuCan03TxMsg2_oTC37X_VCU_CAN03]
    VCU_oTC37X_VCU_CAN12_Rx: communication-direction=IN, i-signal-i-pdus=[VcuCan12RxMsg3_oTC37X_VCU_CAN12, VcuCan12RxMsg4_oTC37X_VCU_CAN12]
    VCU_oTC37X_VCU_CAN12_Tx: communication-direction=OUT, i-signal-i-pdus=[VcuCan12TxMsg1_oTC37X_VCU_CAN12, VcuCan12TxMsg2_oTC37X_VCU_CAN12]
package /PDU
  dcm i pdu MasterReq_ERV_oLIN00: length=8, diag-pdu-type=DIAG-REQUEST
  dcm i pdu MasterReq_EXV_1_oLIN00: length=8, diag-pdu-type=DIAG-REQUEST
  dcm i pdu MasterReq_EXV_2_oLIN00: length=8, diag-pdu-type=DIAG-REQUEST
  dcm i pdu MasterReq_GWM_oLIN01: length=8, diag-pdu-type=DIAG-REQUEST
  dcm i pdu MasterReq_HVCH_oLIN00: length=8, diag-pdu-type=DIAG-REQUEST
  dcm i pdu MasterReq_oLIN00: length=8, diag-pdu-type=DIAG-REQUEST
  dcm i pdu MasterReq_oLIN01: length=8, diag-pdu-type=DIAG-REQUEST
  dcm i pdu MasterReq_PMP_1_oLIN00: length=8, diag-pdu-type=DIAG-REQUEST
  dcm i pdu MasterReq_PMP_2_oLIN00: length=8, diag-pdu-type=DIAG-REQUEST
  dcm i pdu MasterReq_SVA_oLIN00: length=8, diag-pdu-type=DIAG-REQUEST
  dcm i pdu SlaveResp_ERV_oLIN00: length=8, diag-pdu-type=DIAG-RESPONSE
  dcm i pdu SlaveResp_EXV_1_oLIN00: length=8, diag-pdu-type=DIAG-RESPONSE
  dcm i pdu SlaveResp_EXV_2_oLIN00: length=8, diag-pdu-type=DIAG-RESPONSE
  dcm i pdu SlaveResp_GWM_oLIN01: length=8, diag-pdu-type=DIAG-RESPONSE
  dcm i pdu SlaveResp_HVCH_oLIN00: length=8, diag-pdu-type=DIAG-RESPONSE
  dcm i pdu SlaveResp_PMP_1_oLIN00: length=8, diag-pdu-type=DIAG-RESPONSE
  dcm i pdu SlaveResp_PMP_2_oLIN00: length=8, diag-pdu-type=DIAG-RESPONSE
  dcm i pdu SlaveResp_SVA_oLIN00: length=8, diag-pdu-type=DIAG-RESPONSE
  dcm i pdu Vcu_Uds_Func_Request_oTC37X_VCU_CAN00: length=7, diag-pdu-type=DIAG-REQUEST
  dcm i pdu Vcu_Uds_Phy_Request_oTC37X_VCU_CAN00: length=8, diag-pdu-type=DIAG-REQUEST
  dcm i pdu Vcu_Uds_Response_oTC37X_VCU_CAN00: length=8, diag-pdu-type=DIAG-RESPONSE
package /DataType/Unit
  8 x unit:
    U_A: display-name=A
    U_C: display-name=¡ãC
    U_celsius: display-name=celsius
    U_Degree: display-name=Degree
    U_KW: display-name=KW
    U_p: display-name=%
    U_percent: display-name=percent
    U_V: display-name=V
